VERSION ""

NS_ :

BS_:

BU_:
VAL_TABLE_ ETSD5_PRESSURE_Values 65024 "Sensor Elektric Alarm" 64768 "Sensor Not Calibrated" ;
VAL_TABLE_ ETSD3_DiagSteerRequest 4 "Diag Don't Move" 3 "Diag Centre" 2 "Diag Steer Right" 1 "Diag Steer Left" 0 "Diag Inactive" ;
VAL_TABLE_ SPEED_MidPointHyst 1 "Additional MidPointHyst On" 0 "Additional MidPointHyst Off" ;
VAL_TABLE_ SPEED_ValidIndication 4 "Two Reliable Speeds" 3 "One Reliable Speed" 2 "No Reliable Speed But Front Angl" 1 "No Reliable Speed" ;
VAL_TABLE_ SPEED_LeadSpeed 3 "No Valid Speed Decrement" 2 "Lead Speed " 1 "Lead Speed 1" 0 "No Speed Selected" ;
VAL_TABLE_ SPEED_InSpeed 255 "Knorr Kline no data for 80 ms" 254 "Knorr Kline no data in frame" 253 "Knorr Kline Framing Error" 252 "Knorr Kline Cs Error" 251 "Knorr Kline no header for 80ms" 250 "Speed Above 150 km/h" 249 "GPS No message(s) received" 248 "GPS No Fix" 247 "Can Signal not present" 246 "Can Signal not plausible" 245 "Wabco Pulse not present" 244 "Wabco Pulsetime below 150 ms" 243 "C3 Speed Deceleration rate too h" 242 "C3 Speed Kfactor out of range" 241 "C3 Speed Kfactor not stable" 240 "C3 Speed Kfactor not saved in ee" 239 "C3 Speed too loew for validation" ;
VAL_TABLE_ ETSD2_PRESSURE_Values 65024 "Sensor Elektric Alarm" 64768 "Sensor Not Calibrated" ;
VAL_TABLE_ ETSS_SimpleStatusses 32 "Normal" 12 "Normal" 11 "Failure" 10 "Crab" 9 "Manual" 8 "Centring" 7 "Unknown" 6 "Diagnostic" 5 "Failure" 4 "Waiting for Movement" 3 "Initialise" 2 "Checking..." 1 "Failure" 0 "Ok" ;
VAL_TABLE_ ETSD2_ANGLE_Values 65535 "Signal not available" 64510 "Not Defined" 64509 "Not Defined" 64508 "Not Defined" 64507 "Not Defined" 64506 "Not Defined" 64505 "Not Defined" 64504 "Not Defined" 64503 "Not Defined" 64502 "Not Defined" 64501 "Not Defined" 64500 "Not Defined" 64499 "Not Defined" 64498 "Not Defined" 64497 "Not Defined" 64496 "Not Defined" 64495 "Not Defined" 64494 "Not Defined" 64493 "Not Defined" 64492 "Not Defined" 64491 "Not Defined" 64490 "Not Defined" 64489 "Not Defined" 64488 "Not Defined" 64487 "Not Defined" 64486 "Not Defined" 64485 "Not Defined" 64484 "Not Defined" 64483 "Not Defined" 64482 "Not Defined" 64481 "Not Defined" 64480 "Not Defined" 64479 "Not Defined" 64478 "Not Defined" 64477 "Not Defined" 64476 "Not Defined" 64475 "Not Defined" 64474 "Not Defined" 64473 "Not Defined" 64472 "Not Defined" 64471 "Not Defined" 64470 "Not Defined" 64469 "Not Defined" 64468 "Not Defined" 64467 "Not Defined" 64466 "Not Defined" 64465 "Not Defined" 64464 "Not Defined" 64463 "Not Defined" 64462 "Not Defined" 64461 "Not Defined" 64460 "Not Defined" 64459 "Not Defined" 64458 "Not Defined" 64457 "Not Defined" 64456 "Not Defined" 64455 "Not Defined" 64454 "Not Defined" 64453 "Not Defined" 64452 "Not Defined" 64451 "Not Defined" 64450 "Not Defined" 64449 "Not Defined" 64448 "Not Defined" 64447 "Not Defined" 64446 "Not Defined" 64445 "Not Defined" 64444 "Not Defined" 64443 "Not Defined" 64442 "Not Defined" 64441 "Not Defined" 64440 "Not Defined" 64439 "Not Defined" 64438 "Not Defined" 64437 "Not Defined" 64436 "Not Defined" 64435 "Not Defined" 64434 "Not Defined" 64433 "Not Defined" 64432 "Not Defined" 64431 "Not Defined" 64430 "Not Defined" 64429 "Not Defined" 64428 "Not Defined" 64427 "Not Defined" 64426 "Not Defined" 64425 "Not Defined" 64424 "Not Defined" 64423 "Not Defined" 64422 "Not Defined" 64421 "Not Defined" 64420 "Not Defined" 64419 "Not Defined" 64418 "Not Defined" 64417 "Not Defined" 64416 "Not Defined" 64415 "Not Defined" 64414 "Not Defined" 64413 "Not Defined" 64412 "Not Defined" 64411 "Not Defined" 64410 "Not Defined" 64409 "Not Defined" 64408 "Not Defined" 64407 "Not Defined" 64406 "Not Defined" 64405 "Not Defined" 64404 "Not Defined" 64403 "Not Defined" 64402 "Not Defined" 64401 "Not Defined" 64400 "Not Defined" 64399 "Not Defined" 64398 "Not Defined" 64397 "Not Defined" 64396 "Not Defined" 64395 "Not Defined" 64394 "Not Defined" 64393 "Not Defined" 64392 "Not Defined" 64391 "Not Defined" 64390 "Not Defined" 64389 "Not Defined" 64388 "Not Defined" 64387 "Not Defined" 64386 "Not Defined" 64385 "Not Defined" 64384 "Not Defined" 64383 "Not Defined" 64382 "Not Defined" 64381 "Not Defined" 64380 "Not Defined" 64379 "Not Defined" 64378 "Not Defined" 64377 "Not Defined" 64376 "Not Defined" 64375 "Not Defined" 64374 "Not Defined" 64373 "Not Defined" 64372 "Not Defined" 64371 "Not Defined" 64370 "Not Defined" 64369 "Not Defined" 64368 "Not Defined" 64367 "Not Defined" 64366 "Not Defined" 64365 "Not Defined" 64364 "Not Defined" 64363 "Not Defined" 64362 "Not Defined" 64361 "Not Defined" 64360 "Not Defined" 64359 "Not Defined" 64358 "Not Defined" 64357 "Not Defined" 64356 "Not Defined" 64355 "Not Defined" 64354 "Not Defined" 64353 "Not Defined" 64352 "Not Defined" 64351 "Not Defined" 64350 "Not Defined" 64349 "Not Defined" 64348 "Not Defined" 64347 "Not Defined" 64346 "Not Defined" 64345 "Not Defined" 64344 "Not Defined" 64343 "Not Defined" 64342 "Not Defined" 64341 "Not Defined" 64340 "Not Defined" 64339 "Not Defined" 64338 "Not Defined" 64337 "Not Defined" 64336 "Not Defined" 64335 "Not Defined" 64334 "Not Defined" 64333 "Not Defined" 64332 "Not Defined" 64331 "Not Defined" 64330 "Not Defined" 64329 "Not Defined" 64328 "Not Defined" 64327 "Not Defined" 64326 "Not Defined" 64325 "Not Defined" 64324 "Not Defined" 64323 "Not Defined" 64322 "Not Defined" 64321 "Not Defined" 64320 "Not Defined" 64319 "Not Defined" 64318 "Not Defined" 64317 "Not Defined" 64316 "Not Defined" 64315 "Not Defined" 64314 "Not Defined" 64313 "Not Defined" 64312 "Not Defined" 64311 "Not Defined" 64310 "Not Defined" 64309 "Not Defined" 64308 "Not Defined" 64307 "Not Defined" 64306 "Not Defined" 64305 "Not Defined" 64304 "Not Defined" 64303 "Not Defined" 64302 "Not Defined" 64301 "Not Defined" 64300 "Not Defined" 64299 "Not Defined" 64298 "Not Defined" 64297 "Not Defined" 64296 "Not Defined" 64295 "Not Defined" 64294 "Not Defined" 64293 "Not Defined" 64292 "Not Defined" 64291 "Not Defined" 64290 "Not Defined" 64289 "Not Defined" 64288 "Not Defined" 64287 "Not Defined" 64286 "Not Defined" 64285 "Not Defined" 64284 "Not Defined" 64283 "Not Defined" 64282 "Not Defined" 64281 "Not Defined" 64280 "Not Defined" 64279 "Not Defined" 64278 "Not Defined" 64277 "Not Defined" 64276 "Not Defined" 64275 "Not Defined" 64274 "Not Defined" 64273 "Not Defined" 64272 "Not Defined" 64271 "Not Defined" 64270 "Not Defined" 64269 "Not Defined" 64268 "Not Defined" 64267 "Not Defined" 64266 "Not Defined" 64265 "Not Defined" 64264 "Not Defined" 64263 "Not Defined" 64262 "Not Defined" 64261 "Not Defined" 64260 "Not Defined" 64259 "Not Defined" 64258 "Not Defined" 64257 "Not Defined" 64256 "Not Defined" ;
VAL_TABLE_ ETSS_SteerMode_Values 15 "Not Defined" 14 "Not Defined" 13 "Not Defined" 12 "Not Defined" 11 "Not Defined" 10 "Not Defined" 9 "Not Defined" 8 "Not Defined" 7 "Not Defined" 6 "Not Defined" 5 "Not Defined" 4 "Not Defined" 3 "Not Defined" 2 "Crab " 1 "Normal" 0 "Manual" ;
VAL_TABLE_ ETSS_CentringState_Values 1 "ETS System is Active or Passive " 0 "Centring Steering Axle bij Centr" ;
VAL_TABLE_ ETSS_DiagnosticState_Values 1 "Diagnostic Session Active" 0 "No Diagnostic Session Active" ;
VAL_TABLE_ ETSS_AlarmState_Values 1 "Alarm(s) Active" 0 "No alarm active" ;
VAL_TABLE_ ETSS_SteeringState_Values 1 "ETS Operational" 0 "ETS Initialise" ;
VAL_TABLE_ ETSD1_ANGLE_Values 65535 "Signal not available" 64510 "Not Defined" 64509 "Not Defined" 64508 "Not Defined" 64507 "Not Defined" 64506 "Not Defined" 64505 "Not Defined" 64504 "Not Defined" 64503 "Not Defined" 64502 "Not Defined" 64501 "Not Defined" 64500 "Not Defined" 64499 "Not Defined" 64498 "Not Defined" 64497 "Not Defined" 64496 "Not Defined" 64495 "Not Defined" 64494 "Not Defined" 64493 "Not Defined" 64492 "Not Defined" 64491 "Not Defined" 64490 "Not Defined" 64489 "Not Defined" 64488 "Not Defined" 64487 "Not Defined" 64486 "Not Defined" 64485 "Not Defined" 64484 "Not Defined" 64483 "Not Defined" 64482 "Not Defined" 64481 "Not Defined" 64480 "Not Defined" 64479 "Not Defined" 64478 "Not Defined" 64477 "Not Defined" 64476 "Not Defined" 64475 "Not Defined" 64474 "Not Defined" 64473 "Not Defined" 64472 "Not Defined" 64471 "Not Defined" 64470 "Not Defined" 64469 "Not Defined" 64468 "Not Defined" 64467 "Not Defined" 64466 "Not Defined" 64465 "Not Defined" 64464 "Not Defined" 64463 "Not Defined" 64462 "Not Defined" 64461 "Not Defined" 64460 "Not Defined" 64459 "Not Defined" 64458 "Not Defined" 64457 "Not Defined" 64456 "Not Defined" 64455 "Not Defined" 64454 "Not Defined" 64453 "Not Defined" 64452 "Not Defined" 64451 "Not Defined" 64450 "Not Defined" 64449 "Not Defined" 64448 "Not Defined" 64447 "Not Defined" 64446 "Not Defined" 64445 "Not Defined" 64444 "Not Defined" 64443 "Not Defined" 64442 "Not Defined" 64441 "Not Defined" 64440 "Not Defined" 64439 "Not Defined" 64438 "Not Defined" 64437 "Not Defined" 64436 "Not Defined" 64435 "Not Defined" 64434 "Not Defined" 64433 "Not Defined" 64432 "Not Defined" 64431 "Not Defined" 64430 "Not Defined" 64429 "Not Defined" 64428 "Not Defined" 64427 "Not Defined" 64426 "Not Defined" 64425 "Not Defined" 64424 "Not Defined" 64423 "Not Defined" 64422 "Not Defined" 64421 "Not Defined" 64420 "Not Defined" 64419 "Not Defined" 64418 "Not Defined" 64417 "Not Defined" 64416 "Not Defined" 64415 "Not Defined" 64414 "Not Defined" 64413 "Not Defined" 64412 "Not Defined" 64411 "Not Defined" 64410 "Not Defined" 64409 "Not Defined" 64408 "Not Defined" 64407 "Not Defined" 64406 "Not Defined" 64405 "Not Defined" 64404 "Not Defined" 64403 "Not Defined" 64402 "Not Defined" 64401 "Not Defined" 64400 "Not Defined" 64399 "Not Defined" 64398 "Not Defined" 64397 "Not Defined" 64396 "Not Defined" 64395 "Not Defined" 64394 "Not Defined" 64393 "Not Defined" 64392 "Not Defined" 64391 "Not Defined" 64390 "Not Defined" 64389 "Not Defined" 64388 "Not Defined" 64387 "Not Defined" 64386 "Not Defined" 64385 "Not Defined" 64384 "Not Defined" 64383 "Not Defined" 64382 "Not Defined" 64381 "Not Defined" 64380 "Not Defined" 64379 "Not Defined" 64378 "Not Defined" 64377 "Not Defined" 64376 "Not Defined" 64375 "Not Defined" 64374 "Not Defined" 64373 "Not Defined" 64372 "Not Defined" 64371 "Not Defined" 64370 "Not Defined" 64369 "Not Defined" 64368 "Not Defined" 64367 "Not Defined" 64366 "Not Defined" 64365 "Not Defined" 64364 "Not Defined" 64363 "Not Defined" 64362 "Not Defined" 64361 "Not Defined" 64360 "Not Defined" 64359 "Not Defined" 64358 "Not Defined" 64357 "Not Defined" 64356 "Not Defined" 64355 "Not Defined" 64354 "Not Defined" 64353 "Not Defined" 64352 "Not Defined" 64351 "Not Defined" 64350 "Not Defined" 64349 "Not Defined" 64348 "Not Defined" 64347 "Not Defined" 64346 "Not Defined" 64345 "Not Defined" 64344 "Not Defined" 64343 "Not Defined" 64342 "Not Defined" 64341 "Not Defined" 64340 "Not Defined" 64339 "Not Defined" 64338 "Not Defined" 64337 "Not Defined" 64336 "Not Defined" 64335 "Not Defined" 64334 "Not Defined" 64333 "Not Defined" 64332 "Not Defined" 64331 "Not Defined" 64330 "Not Defined" 64329 "Not Defined" 64328 "Not Defined" 64327 "Not Defined" 64326 "Not Defined" 64325 "Not Defined" 64324 "Not Defined" 64323 "Not Defined" 64322 "Not Defined" 64321 "Not Defined" 64320 "Not Defined" 64319 "Not Defined" 64318 "Not Defined" 64317 "Not Defined" 64316 "Not Defined" 64315 "Not Defined" 64314 "Not Defined" 64313 "Not Defined" 64312 "Not Defined" 64311 "Not Defined" 64310 "Not Defined" 64309 "Not Defined" 64308 "Not Defined" 64307 "Not Defined" 64306 "Not Defined" 64305 "Not Defined" 64304 "Not Defined" 64303 "Not Defined" 64302 "Not Defined" 64301 "Not Defined" 64300 "Not Defined" 64299 "Not Defined" 64298 "Not Defined" 64297 "Not Defined" 64296 "Not Defined" 64295 "Not Defined" 64294 "Not Defined" 64293 "Not Defined" 64292 "Not Defined" 64291 "Not Defined" 64290 "Not Defined" 64289 "Not Defined" 64288 "Not Defined" 64287 "Not Defined" 64286 "Not Defined" 64285 "Not Defined" 64284 "Not Defined" 64283 "Not Defined" 64282 "Not Defined" 64281 "Not Defined" 64280 "Not Defined" 64279 "Not Defined" 64278 "Not Defined" 64277 "Not Defined" 64276 "Not Defined" 64275 "Not Defined" 64274 "Not Defined" 64273 "Not Defined" 64272 "Not Defined" 64271 "Not Defined" 64270 "Not Defined" 64269 "Not Defined" 64268 "Not Defined" 64267 "Not Defined" 64266 "Not Defined" 64265 "Not Defined" 64264 "Not Defined" 64263 "Not Defined" 64262 "Not Defined" 64261 "Not Defined" 64260 "Not Defined" 64259 "Not Defined" 64258 "Not Defined" 64257 "Not Defined" 64256 "Not Defined" ;
VAL_TABLE_ ETSD1_SPEED_Values 255 "Signal not Available" 254 "not defined" 253 "not defined" 252 "not defined" 251 "not defined" ;
VAL_TABLE_ KSD_Values 255 "Signal not Available" 254 "not defined" 253 "not defined" 252 "not defined" 251 "not defined" ;
VAL_TABLE_ DIV_Values 3 "Signal not Available" 2 "Failure/Incorrect Status" 1 "Input is High" 0 "Input is Low" ;
VAL_TABLE_ AIV_Values 65534 "Not Defined" 65533 "Not Defined" 65532 "Not Defined" 65531 "Not Defined" 65530 "Not Defined" 65529 "Not Defined" 65528 "Not Defined" 65527 "Not Defined" 65526 "Not Defined" 65525 "Not Defined" 65524 "Not Defined" 65523 "Not Defined" 65522 "Not Defined" 65521 "Not Defined" 65520 "Not Defined" 65519 "Not Defined" 65518 "Not Defined" 65517 "Not Defined" 65516 "Not Defined" 65515 "Not Defined" 65514 "Not Defined" 65513 "Not Defined" 65512 "Not Defined" 65511 "Not Defined" 65510 "Not Defined" 65509 "Not Defined" 65508 "Not Defined" 65507 "Not Defined" 65506 "Not Defined" 65505 "Not Defined" 65504 "Not Defined" 65503 "Not Defined" 65502 "Not Defined" 65501 "Not Defined" 65500 "Not Defined" 65499 "Not Defined" 65498 "Not Defined" 65497 "Not Defined" 65496 "Not Defined" 65495 "Not Defined" 65494 "Not Defined" 65493 "Not Defined" 65492 "Not Defined" 65491 "Not Defined" 65490 "Not Defined" 65489 "Not Defined" 65488 "Not Defined" 65487 "Not Defined" 65486 "Not Defined" 65485 "Not Defined" 65484 "Not Defined" 65483 "Not Defined" 65482 "Not Defined" 65481 "Not Defined" 65480 "Not Defined" 65479 "Not Defined" 65478 "Not Defined" 65477 "Not Defined" 65476 "Not Defined" 65475 "Not Defined" 65474 "Not Defined" 65473 "Not Defined" 65472 "Not Defined" 65471 "Not Defined" 65470 "Not Defined" 65469 "Not Defined" 65468 "Not Defined" 65467 "Not Defined" 65466 "Not Defined" 65465 "Not Defined" 65464 "Not Defined" 65463 "Not Defined" 65462 "Not Defined" 65461 "Not Defined" 65460 "Not Defined" 65459 "Not Defined" 65458 "Not Defined" 65457 "Not Defined" 65456 "Not Defined" 65455 "Not Defined" 65454 "Not Defined" 65453 "Not Defined" 65452 "Not Defined" 65451 "Not Defined" 65450 "Not Defined" 65449 "Not Defined" 65448 "Not Defined" 65447 "Not Defined" 65446 "Not Defined" 65445 "Not Defined" 65444 "Not Defined" 65443 "Not Defined" 65442 "Not Defined" 65441 "Not Defined" 65440 "Not Defined" 65439 "Not Defined" 65438 "Not Defined" 65437 "Not Defined" 65436 "Not Defined" 65435 "Not Defined" 65434 "Not Defined" 65433 "Not Defined" 65432 "Not Defined" 65431 "Not Defined" 65430 "Not Defined" 65429 "Not Defined" 65428 "Not Defined" 65427 "Not Defined" 65426 "Not Defined" 65425 "Not Defined" 65424 "Not Defined" 65423 "Not Defined" 65422 "Not Defined" 65421 "Not Defined" 65420 "Not Defined" 65419 "Not Defined" 65418 "Not Defined" 65417 "Not Defined" 65416 "Not Defined" 65415 "Not Defined" 65414 "Not Defined" 65413 "Not Defined" 65412 "Not Defined" 65411 "Not Defined" 65410 "Not Defined" 65409 "Not Defined" 65408 "Not Defined" 65407 "Not Defined" 65406 "Not Defined" 65405 "Not Defined" 65404 "Not Defined" 65403 "Not Defined" 65402 "Not Defined" 65401 "Not Defined" 65400 "Not Defined" 65399 "Not Defined" 65398 "Not Defined" 65397 "Not Defined" 65396 "Not Defined" 65395 "Not Defined" 65394 "Not Defined" 65393 "Not Defined" 65392 "Not Defined" 65391 "Not Defined" 65390 "Not Defined" 65389 "Not Defined" 65388 "Not Defined" 65387 "Not Defined" 65386 "Not Defined" 65385 "Not Defined" 65384 "Not Defined" 65383 "Not Defined" 65382 "Not Defined" 65381 "Not Defined" 65380 "Not Defined" 65379 "Not Defined" 65378 "Not Defined" 65377 "Not Defined" 65376 "Not Defined" 65375 "Not Defined" 65374 "Not Defined" 65373 "Not Defined" 65372 "Not Defined" 65371 "Not Defined" 65370 "Not Defined" 65369 "Not Defined" 65368 "Not Defined" 65367 "Not Defined" 65366 "Not Defined" 65365 "Not Defined" 65364 "Not Defined" 65363 "Not Defined" 65362 "Not Defined" 65361 "Not Defined" 65360 "Not Defined" 65359 "Not Defined" 65358 "Not Defined" 65357 "Not Defined" 65356 "Not Defined" 65355 "Not Defined" 65354 "Not Defined" 65353 "Not Defined" 65352 "Not Defined" 65351 "Not Defined" 65350 "Not Defined" 65349 "Not Defined" 65348 "Not Defined" 65347 "Not Defined" 65346 "Not Defined" 65345 "Not Defined" 65344 "Not Defined" 65343 "Not Defined" 65342 "Not Defined" 65341 "Not Defined" 65340 "Not Defined" 65339 "Not Defined" 65338 "Not Defined" 65337 "Not Defined" 65336 "Not Defined" 65335 "Not Defined" 65334 "Not Defined" 65333 "Not Defined" 65332 "Not Defined" 65331 "Not Defined" 65330 "Not Defined" 65329 "Not Defined" 65328 "Not Defined" 65327 "Not Defined" 65326 "Not Defined" 65325 "Not Defined" 65324 "Not Defined" 65323 "Not Defined" 65322 "Not Defined" 65321 "Not Defined" 65320 "Not Defined" 65319 "Not Defined" 65318 "Not Defined" 65317 "Not Defined" 65316 "Not Defined" 65315 "Not Defined" 65314 "Not Defined" 65313 "Not Defined" 65312 "Not Defined" 65311 "Not Defined" 65310 "Not Defined" 65309 "Not Defined" 65308 "Not Defined" 65307 "Not Defined" 65306 "Not Defined" 65305 "Not Defined" 65304 "Not Defined" 65303 "Not Defined" 65302 "Not Defined" 65301 "Not Defined" 65300 "Not Defined" 65299 "Not Defined" 65298 "Not Defined" 65297 "Not Defined" 65296 "Not Defined" 65295 "Not Defined" 65294 "Not Defined" 65293 "Not Defined" 65292 "Not Defined" 65291 "Not Defined" 65290 "Not Defined" 65289 "Not Defined" 65288 "Not Defined" 65287 "Not Defined" 65286 "Not Defined" 65285 "Not Defined" 65284 "Not Defined" 65283 "Not Defined" 65282 "Not Defined" 65281 "Not Defined" 65280 "Not Defined" 65279 "Not Defined" 65278 "Not Defined" 65277 "Not Defined" 65276 "Not Defined" 65275 "Not Defined" 65274 "Not Defined" 65273 "Not Defined" 65272 "Not Defined" 65271 "Not Defined" 65270 "Not Defined" 65269 "Not Defined" 65268 "Not Defined" 65267 "Not Defined" 65266 "Not Defined" 65265 "Not Defined" 65264 "Not Defined" 65263 "Not Defined" 65262 "Not Defined" 65261 "Not Defined" 65260 "Not Defined" 65259 "Not Defined" 65258 "Not Defined" 65257 "Not Defined" 65256 "Not Defined" 65255 "Not Defined" 65254 "Not Defined" 65253 "Not Defined" 65252 "Not Defined" 65251 "Not Defined" 65250 "Not Defined" 65249 "Not Defined" 65248 "Not Defined" 65247 "Not Defined" 65246 "Not Defined" 65245 "Not Defined" 65244 "Not Defined" 65243 "Not Defined" 65242 "Not Defined" 65241 "Not Defined" 65240 "Not Defined" 65239 "Not Defined" 65238 "Not Defined" 65237 "Not Defined" 65236 "Not Defined" 65235 "Not Defined" 65234 "Not Defined" 65233 "Not Defined" 65232 "Not Defined" 65231 "Not Defined" 65230 "Not Defined" 65229 "Not Defined" 65228 "Not Defined" 65227 "Not Defined" 65226 "Not Defined" 65225 "Not Defined" 65224 "Not Defined" 65223 "Not Defined" 65222 "Not Defined" 65221 "Not Defined" 65220 "Not Defined" 65219 "Not Defined" 65218 "Not Defined" 65217 "Not Defined" 65216 "Not Defined" 65215 "Not Defined" 65214 "Not Defined" 65213 "Not Defined" 65212 "Not Defined" 65211 "Not Defined" 65210 "Not Defined" 65209 "Not Defined" 65208 "Not Defined" 65207 "Not Defined" 65206 "Not Defined" 65205 "Not Defined" 65204 "Not Defined" 65203 "Not Defined" 65202 "Not Defined" 65201 "Not Defined" 65200 "Not Defined" 65199 "Not Defined" 65198 "Not Defined" 65197 "Not Defined" 65196 "Not Defined" 65195 "Not Defined" 65194 "Not Defined" 65193 "Not Defined" 65192 "Not Defined" 65191 "Not Defined" 65190 "Not Defined" 65189 "Not Defined" 65188 "Not Defined" 65187 "Not Defined" 65186 "Not Defined" 65185 "Not Defined" 65184 "Not Defined" 65183 "Not Defined" 65182 "Not Defined" 65181 "Not Defined" 65180 "Not Defined" 65179 "Not Defined" 65178 "Not Defined" 65177 "Not Defined" 65176 "Not Defined" 65175 "Not Defined" 65174 "Not Defined" 65173 "Not Defined" 65172 "Not Defined" 65171 "Not Defined" 65170 "Not Defined" 65169 "Not Defined" 65168 "Not Defined" 65167 "Not Defined" 65166 "Not Defined" 65165 "Not Defined" 65164 "Not Defined" 65163 "Not Defined" 65162 "Not Defined" 65161 "Not Defined" 65160 "Not Defined" 65159 "Not Defined" 65158 "Not Defined" 65157 "Not Defined" 65156 "Not Defined" 65155 "Not Defined" 65154 "Not Defined" 65153 "Not Defined" 65152 "Not Defined" 65151 "Not Defined" 65150 "Not Defined" 65149 "Not Defined" 65148 "Not Defined" 65147 "Not Defined" 65146 "Not Defined" 65145 "Not Defined" 65144 "Not Defined" 65143 "Not Defined" 65142 "Not Defined" 65141 "Not Defined" 65140 "Not Defined" 65139 "Not Defined" 65138 "Not Defined" 65137 "Not Defined" 65136 "Not Defined" 65135 "Not Defined" 65134 "Not Defined" 65133 "Not Defined" 65132 "Not Defined" 65131 "Not Defined" 65130 "Not Defined" 65129 "Not Defined" 65128 "Not Defined" 65127 "Not Defined" 65126 "Not Defined" 65125 "Not Defined" 65124 "Not Defined" 65123 "Not Defined" 65122 "Not Defined" 65121 "Not Defined" 65120 "Not Defined" 65119 "Not Defined" 65118 "Not Defined" 65117 "Not Defined" 65116 "Not Defined" 65115 "Not Defined" 65114 "Not Defined" 65113 "Not Defined" 65112 "Not Defined" 65111 "Not Defined" 65110 "Not Defined" 65109 "Not Defined" 65108 "Not Defined" 65107 "Not Defined" 65106 "Not Defined" 65105 "Not Defined" 65104 "Not Defined" 65103 "Not Defined" 65102 "Not Defined" 65101 "Not Defined" 65100 "Not Defined" 65099 "Not Defined" 65098 "Not Defined" 65097 "Not Defined" 65096 "Not Defined" 65095 "Not Defined" 65094 "Not Defined" 65093 "Not Defined" 65092 "Not Defined" 65091 "Not Defined" 65090 "Not Defined" 65089 "Not Defined" 65088 "Not Defined" 65087 "Not Defined" 65086 "Not Defined" 65085 "Not Defined" 65084 "Not Defined" 65083 "Not Defined" 65082 "Not Defined" 65081 "Not Defined" 65080 "Not Defined" 65079 "Not Defined" 65078 "Not Defined" 65077 "Not Defined" 65076 "Not Defined" 65075 "Not Defined" 65074 "Not Defined" 65073 "Not Defined" 65072 "Not Defined" 65071 "Not Defined" 65070 "Not Defined" 65069 "Not Defined" 65068 "Not Defined" 65067 "Not Defined" 65066 "Not Defined" 65065 "Not Defined" 65064 "Not Defined" 65063 "Not Defined" 65062 "Not Defined" 65061 "Not Defined" 65060 "Not Defined" 65059 "Not Defined" 65058 "Not Defined" 65057 "Not Defined" 65056 "Not Defined" 65055 "Not Defined" 65054 "Not Defined" 65053 "Not Defined" 65052 "Not Defined" 65051 "Not Defined" 65050 "Not Defined" 65049 "Not Defined" 65048 "Not Defined" 65047 "Not Defined" 65046 "Not Defined" 65045 "Not Defined" 65044 "Not Defined" 65043 "Not Defined" 65042 "Not Defined" 65041 "Not Defined" 65040 "Not Defined" 65039 "Not Defined" 65038 "Not Defined" 65037 "Not Defined" 65036 "Not Defined" 65035 "Not Defined" 65034 "Not Defined" 65033 "Not Defined" 65032 "Not Defined" 65031 "Not Defined" 65030 "Not Defined" 65029 "Not Defined" 65028 "Not Defined" 65027 "Not Defined" 65026 "Not Defined" 65025 "Not Defined" 65024 "Not Defined" 65023 "Not Defined" 65022 "Not Defined" 65021 "Not Defined" 65020 "Not Defined" 65019 "Not Defined" 65018 "Not Defined" 65017 "Not Defined" 65016 "Not Defined" 65015 "Not Defined" 65014 "Not Defined" 65013 "Not Defined" 65012 "Not Defined" 65011 "Not Defined" 65010 "Not Defined" 65009 "Not Defined" 65008 "Not Defined" 65007 "Not Defined" 65006 "Not Defined" 65005 "Not Defined" 65004 "Not Defined" 65003 "Not Defined" 65002 "Not Defined" 65001 "Not Defined" 65000 "Not Defined" 64999 "Not Defined" 64998 "Not Defined" 64997 "Not Defined" 64996 "Not Defined" 64995 "Not Defined" 64994 "Not Defined" 64993 "Not Defined" 64992 "Not Defined" 64991 "Not Defined" 64990 "Not Defined" 64989 "Not Defined" 64988 "Not Defined" 64987 "Not Defined" 64986 "Not Defined" 64985 "Not Defined" 64984 "Not Defined" 64983 "Not Defined" 64982 "Not Defined" 64981 "Not Defined" 64980 "Not Defined" 64979 "Not Defined" 64978 "Not Defined" 64977 "Not Defined" 64976 "Not Defined" 64975 "Not Defined" 64974 "Not Defined" 64973 "Not Defined" 64972 "Not Defined" 64971 "Not Defined" 64970 "Not Defined" 64969 "Not Defined" 64968 "Not Defined" 64967 "Not Defined" 64966 "Not Defined" 64965 "Not Defined" 64964 "Not Defined" 64963 "Not Defined" 64962 "Not Defined" 64961 "Not Defined" 64960 "Not Defined" 64959 "Not Defined" 64958 "Not Defined" 64957 "Not Defined" 64956 "Not Defined" 64955 "Not Defined" 64954 "Not Defined" 64953 "Not Defined" 64952 "Not Defined" 64951 "Not Defined" 64950 "Not Defined" 64949 "Not Defined" 64948 "Not Defined" 64947 "Not Defined" 64946 "Not Defined" 64945 "Not Defined" 64944 "Not Defined" 64943 "Not Defined" 64942 "Not Defined" 64941 "Not Defined" 64940 "Not Defined" 64939 "Not Defined" 64938 "Not Defined" 64937 "Not Defined" 64936 "Not Defined" 64935 "Not Defined" 64934 "Not Defined" 64933 "Not Defined" 64932 "Not Defined" 64931 "Not Defined" 64930 "Not Defined" 64929 "Not Defined" 64928 "Not Defined" 64927 "Not Defined" 64926 "Not Defined" 64925 "Not Defined" 64924 "Not Defined" 64923 "Not Defined" 64922 "Not Defined" 64921 "Not Defined" 64920 "Not Defined" 64919 "Not Defined" 64918 "Not Defined" 64917 "Not Defined" 64916 "Not Defined" 64915 "Not Defined" 64914 "Not Defined" 64913 "Not Defined" 64912 "Not Defined" 64911 "Not Defined" 64910 "Not Defined" 64909 "Not Defined" 64908 "Not Defined" 64907 "Not Defined" 64906 "Not Defined" 64905 "Not Defined" 64904 "Not Defined" 64903 "Not Defined" 64902 "Not Defined" 64901 "Not Defined" 64900 "Not Defined" 64899 "Not Defined" 64898 "Not Defined" 64897 "Not Defined" 64896 "Not Defined" 64895 "Not Defined" 64894 "Not Defined" 64893 "Not Defined" 64892 "Not Defined" 64891 "Not Defined" 64890 "Not Defined" 64889 "Not Defined" 64888 "Not Defined" 64887 "Not Defined" 64886 "Not Defined" 64885 "Not Defined" 64884 "Not Defined" 64883 "Not Defined" 64882 "Not Defined" 64881 "Not Defined" 64880 "Not Defined" 64879 "Not Defined" 64878 "Not Defined" 64877 "Not Defined" 64876 "Not Defined" 64875 "Not Defined" 64874 "Not Defined" 64873 "Not Defined" 64872 "Not Defined" 64871 "Not Defined" 64870 "Not Defined" 64869 "Not Defined" 64868 "Not Defined" 64867 "Not Defined" 64866 "Not Defined" 64865 "Not Defined" 64864 "Not Defined" 64863 "Not Defined" 64862 "Not Defined" 64861 "Not Defined" 64860 "Not Defined" 64859 "Not Defined" 64858 "Not Defined" 64857 "Not Defined" 64856 "Not Defined" 64855 "Not Defined" 64854 "Not Defined" 64853 "Not Defined" 64852 "Not Defined" 64851 "Not Defined" 64850 "Not Defined" 64849 "Not Defined" 64848 "Not Defined" 64847 "Not Defined" 64846 "Not Defined" 64845 "Not Defined" 64844 "Not Defined" 64843 "Not Defined" 64842 "Not Defined" 64841 "Not Defined" 64840 "Not Defined" 64839 "Not Defined" 64838 "Not Defined" 64837 "Not Defined" 64836 "Not Defined" 64835 "Not Defined" 64834 "Not Defined" 64833 "Not Defined" 64832 "Not Defined" 64831 "Not Defined" 64830 "Not Defined" 64829 "Not Defined" 64828 "Not Defined" 64827 "Not Defined" 64826 "Not Defined" 64825 "Not Defined" 64824 "Not Defined" 64823 "Not Defined" 64822 "Not Defined" 64821 "Not Defined" 64820 "Not Defined" 64819 "Not Defined" 64818 "Not Defined" 64817 "Not Defined" 64816 "Not Defined" 64815 "Not Defined" 64814 "Not Defined" 64813 "Not Defined" 64812 "Not Defined" 64811 "Not Defined" 64810 "Not Defined" 64809 "Not Defined" 64808 "Not Defined" 64807 "Not Defined" 64806 "Not Defined" 64805 "Not Defined" 64804 "Not Defined" 64803 "Not Defined" 64802 "Not Defined" 64801 "Not Defined" 64800 "Not Defined" 64799 "Not Defined" 64798 "Not Defined" 64797 "Not Defined" 64796 "Not Defined" 64795 "Not Defined" 64794 "Not Defined" 64793 "Not Defined" 64792 "Not Defined" 64791 "Not Defined" 64790 "Not Defined" 64789 "Not Defined" 64788 "Not Defined" 64787 "Not Defined" 64786 "Not Defined" 64785 "Not Defined" 64784 "Not Defined" 64783 "Not Defined" 64782 "Not Defined" 64781 "Not Defined" 64780 "Not Defined" 64779 "Not Defined" 64778 "Not Defined" 64777 "Not Defined" 64776 "Not Defined" 64775 "Not Defined" 64774 "Not Defined" 64773 "Not Defined" 64772 "Not Defined" 64771 "Not Defined" 64770 "Not Defined" 64769 "Not Defined" 64768 "Not Defined" 64767 "Not Defined" 64766 "Not Defined" 64765 "Not Defined" 64764 "Not Defined" 64763 "Not Defined" 64762 "Not Defined" 64761 "Not Defined" 64760 "Not Defined" 64759 "Not Defined" 64758 "Not Defined" 64757 "Not Defined" 64756 "Not Defined" 64755 "Not Defined" 64754 "Not Defined" 64753 "Not Defined" 64752 "Not Defined" 64751 "Not Defined" 64750 "Not Defined" 64749 "Not Defined" 64748 "Not Defined" 64747 "Not Defined" 64746 "Not Defined" 64745 "Not Defined" 64744 "Not Defined" 64743 "Not Defined" 64742 "Not Defined" 64741 "Not Defined" 64740 "Not Defined" 64739 "Not Defined" 64738 "Not Defined" 64737 "Not Defined" 64736 "Not Defined" 64735 "Not Defined" 64734 "Not Defined" 64733 "Not Defined" 64732 "Not Defined" 64731 "Not Defined" 64730 "Not Defined" 64729 "Not Defined" 64728 "Not Defined" 64727 "Not Defined" 64726 "Not Defined" 64725 "Not Defined" 64724 "Not Defined" 64723 "Not Defined" 64722 "Not Defined" 64721 "Not Defined" 64720 "Not Defined" 64719 "Not Defined" 64718 "Not Defined" 64717 "Not Defined" 64716 "Not Defined" 64715 "Not Defined" 64714 "Not Defined" 64713 "Not Defined" 64712 "Not Defined" 64711 "Not Defined" 64710 "Not Defined" 64709 "Not Defined" 64708 "Not Defined" 64707 "Not Defined" 64706 "Not Defined" 64705 "Not Defined" 64704 "Not Defined" 64703 "Not Defined" 64702 "Not Defined" 64701 "Not Defined" 64700 "Not Defined" 64699 "Not Defined" 64698 "Not Defined" 64697 "Not Defined" 64696 "Not Defined" 64695 "Not Defined" 64694 "Not Defined" 64693 "Not Defined" 64692 "Not Defined" 64691 "Not Defined" 64690 "Not Defined" 64689 "Not Defined" 64688 "Not Defined" 64687 "Not Defined" 64686 "Not Defined" 64685 "Not Defined" 64684 "Not Defined" 64683 "Not Defined" 64682 "Not Defined" 64681 "Not Defined" 64680 "Not Defined" 64679 "Not Defined" 64678 "Not Defined" 64677 "Not Defined" 64676 "Not Defined" 64675 "Not Defined" 64674 "Not Defined" 64673 "Not Defined" 64672 "Not Defined" 64671 "Not Defined" 64670 "Not Defined" 64669 "Not Defined" 64668 "Not Defined" 64667 "Not Defined" 64666 "Not Defined" 64665 "Not Defined" 64664 "Not Defined" 64663 "Not Defined" 64662 "Not Defined" 64661 "Not Defined" 64660 "Not Defined" 64659 "Not Defined" 64658 "Not Defined" 64657 "Not Defined" 64656 "Not Defined" 64655 "Not Defined" 64654 "Not Defined" 64653 "Not Defined" 64652 "Not Defined" 64651 "Not Defined" 64650 "Not Defined" 64649 "Not Defined" 64648 "Not Defined" 64647 "Not Defined" 64646 "Not Defined" 64645 "Not Defined" 64644 "Not Defined" 64643 "Not Defined" 64642 "Not Defined" 64641 "Not Defined" 64640 "Not Defined" 64639 "Not Defined" 64638 "Not Defined" 64637 "Not Defined" 64636 "Not Defined" 64635 "Not Defined" 64634 "Not Defined" 64633 "Not Defined" 64632 "Not Defined" 64631 "Not Defined" 64630 "Not Defined" 64629 "Not Defined" 64628 "Not Defined" 64627 "Not Defined" 64626 "Not Defined" 64625 "Not Defined" 64624 "Not Defined" 64623 "Not Defined" 64622 "Not Defined" 64621 "Not Defined" 64620 "Not Defined" 64619 "Not Defined" 64618 "Not Defined" 64617 "Not Defined" 64616 "Not Defined" 64615 "Not Defined" 64614 "Not Defined" 64613 "Not Defined" 64612 "Not Defined" 64611 "Not Defined" 64610 "Not Defined" 64609 "Not Defined" 64608 "Not Defined" 64607 "Not Defined" 64606 "Not Defined" 64605 "Not Defined" 64604 "Not Defined" 64603 "Not Defined" 64602 "Not Defined" 64601 "Not Defined" 64600 "Not Defined" 64599 "Not Defined" 64598 "Not Defined" 64597 "Not Defined" 64596 "Not Defined" 64595 "Not Defined" 64594 "Not Defined" 64593 "Not Defined" 64592 "Not Defined" 64591 "Not Defined" 64590 "Not Defined" 64589 "Not Defined" 64588 "Not Defined" 64587 "Not Defined" 64586 "Not Defined" 64585 "Not Defined" 64584 "Not Defined" 64583 "Not Defined" 64582 "Not Defined" 64581 "Not Defined" 64580 "Not Defined" 64579 "Not Defined" 64578 "Not Defined" 64577 "Not Defined" 64576 "Not Defined" 64575 "Not Defined" 64574 "Not Defined" 64573 "Not Defined" 64572 "Not Defined" 64571 "Not Defined" 64570 "Not Defined" 64569 "Not Defined" 64568 "Not Defined" 64567 "Not Defined" 64566 "Not Defined" 64565 "Not Defined" 64564 "Not Defined" 64563 "Not Defined" 64562 "Not Defined" 64561 "Not Defined" 64560 "Not Defined" 64559 "Not Defined" 64558 "Not Defined" 64557 "Not Defined" 64556 "Not Defined" 64555 "Not Defined" 64554 "Not Defined" 64553 "Not Defined" 64552 "Not Defined" 64551 "Not Defined" 64550 "Not Defined" 64549 "Not Defined" 64548 "Not Defined" 64547 "Not Defined" 64546 "Not Defined" 64545 "Not Defined" 64544 "Not Defined" 64543 "Not Defined" 64542 "Not Defined" 64541 "Not Defined" 64540 "Not Defined" 64539 "Not Defined" 64538 "Not Defined" 64537 "Not Defined" 64536 "Not Defined" 64535 "Not Defined" 64534 "Not Defined" 64533 "Not Defined" 64532 "Not Defined" 64531 "Not Defined" 64530 "Not Defined" 64529 "Not Defined" 64528 "Not Defined" 64527 "Not Defined" 64526 "Not Defined" 64525 "Not Defined" 64524 "Not Defined" 64523 "Not Defined" 64522 "Not Defined" 64521 "Not Defined" 64520 "Not Defined" 64519 "Not Defined" 64518 "Not Defined" 64517 "Not Defined" 64516 "Not Defined" 64515 "Not Defined" 64514 "Not Defined" 64513 "Not Defined" 64512 "Not Defined" 64511 "Not Defined" 65535 "Signal not available" 64510 "Not Defined" 64509 "Not Defined" 64508 "Not Defined" 64507 "Not Defined" 64506 "Not Defined" 64505 "Not Defined" 64504 "Not Defined" 64503 "Not Defined" 64502 "Not Defined" 64501 "Not Defined" 64500 "Not Defined" 64499 "Not Defined" 64498 "Not Defined" 64497 "Not Defined" 64496 "Not Defined" 64495 "Not Defined" 64494 "Not Defined" 64493 "Not Defined" 64492 "Not Defined" 64491 "Not Defined" 64490 "Not Defined" 64489 "Not Defined" 64488 "Not Defined" 64487 "Not Defined" 64486 "Not Defined" 64485 "Not Defined" 64484 "Not Defined" 64483 "Not Defined" 64482 "Not Defined" 64481 "Not Defined" 64480 "Not Defined" 64479 "Not Defined" 64478 "Not Defined" 64477 "Not Defined" 64476 "Not Defined" 64475 "Not Defined" 64474 "Not Defined" 64473 "Not Defined" 64472 "Not Defined" 64471 "Not Defined" 64470 "Not Defined" 64469 "Not Defined" 64468 "Not Defined" 64467 "Not Defined" 64466 "Not Defined" 64465 "Not Defined" 64464 "Not Defined" 64463 "Not Defined" 64462 "Not Defined" 64461 "Not Defined" 64460 "Not Defined" 64459 "Not Defined" 64458 "Not Defined" 64457 "Not Defined" 64456 "Not Defined" 64455 "Not Defined" 64454 "Not Defined" 64453 "Not Defined" 64452 "Not Defined" 64451 "Not Defined" 64450 "Not Defined" 64449 "Not Defined" 64448 "Not Defined" 64447 "Not Defined" 64446 "Not Defined" 64445 "Not Defined" 64444 "Not Defined" 64443 "Not Defined" 64442 "Not Defined" 64441 "Not Defined" 64440 "Not Defined" 64439 "Not Defined" 64438 "Not Defined" 64437 "Not Defined" 64436 "Not Defined" 64435 "Not Defined" 64434 "Not Defined" 64433 "Not Defined" 64432 "Not Defined" 64431 "Not Defined" 64430 "Not Defined" 64429 "Not Defined" 64428 "Not Defined" 64427 "Not Defined" 64426 "Not Defined" 64425 "Not Defined" 64424 "Not Defined" 64423 "Not Defined" 64422 "Not Defined" 64421 "Not Defined" 64420 "Not Defined" 64419 "Not Defined" 64418 "Not Defined" 64417 "Not Defined" 64416 "Not Defined" 64415 "Not Defined" 64414 "Not Defined" 64413 "Not Defined" 64412 "Not Defined" 64411 "Not Defined" 64410 "Not Defined" 64409 "Not Defined" 64408 "Not Defined" 64407 "Not Defined" 64406 "Not Defined" 64405 "Not Defined" 64404 "Not Defined" 64403 "Not Defined" 64402 "Not Defined" 64401 "Not Defined" 64400 "Not Defined" 64399 "Not Defined" 64398 "Not Defined" 64397 "Not Defined" 64396 "Not Defined" 64395 "Not Defined" 64394 "Not Defined" 64393 "Not Defined" 64392 "Not Defined" 64391 "Not Defined" 64390 "Not Defined" 64389 "Not Defined" 64388 "Not Defined" 64387 "Not Defined" 64386 "Not Defined" 64385 "Not Defined" 64384 "Not Defined" 64383 "Not Defined" 64382 "Not Defined" 64381 "Not Defined" 64380 "Not Defined" 64379 "Not Defined" 64378 "Not Defined" 64377 "Not Defined" 64376 "Not Defined" 64375 "Not Defined" 64374 "Not Defined" 64373 "Not Defined" 64372 "Not Defined" 64371 "Not Defined" 64370 "Not Defined" 64369 "Not Defined" 64368 "Not Defined" 64367 "Not Defined" 64366 "Not Defined" 64365 "Not Defined" 64364 "Not Defined" 64363 "Not Defined" 64362 "Not Defined" 64361 "Not Defined" 64360 "Not Defined" 64359 "Not Defined" 64358 "Not Defined" 64357 "Not Defined" 64356 "Not Defined" 64355 "Not Defined" 64354 "Not Defined" 64353 "Not Defined" 64352 "Not Defined" 64351 "Not Defined" 64350 "Not Defined" 64349 "Not Defined" 64348 "Not Defined" 64347 "Not Defined" 64346 "Not Defined" 64345 "Not Defined" 64344 "Not Defined" 64343 "Not Defined" 64342 "Not Defined" 64341 "Not Defined" 64340 "Not Defined" 64339 "Not Defined" 64338 "Not Defined" 64337 "Not Defined" 64336 "Not Defined" 64335 "Not Defined" 64334 "Not Defined" 64333 "Not Defined" 64332 "Not Defined" 64331 "Not Defined" 64330 "Not Defined" 64329 "Not Defined" 64328 "Not Defined" 64327 "Not Defined" 64326 "Not Defined" 64325 "Not Defined" 64324 "Not Defined" 64323 "Not Defined" 64322 "Not Defined" 64321 "Not Defined" 64320 "Not Defined" 64319 "Not Defined" 64318 "Not Defined" 64317 "Not Defined" 64316 "Not Defined" 64315 "Not Defined" 64314 "Not Defined" 64313 "Not Defined" 64312 "Not Defined" 64311 "Not Defined" 64310 "Not Defined" 64309 "Not Defined" 64308 "Not Defined" 64307 "Not Defined" 64306 "Not Defined" 64305 "Not Defined" 64304 "Not Defined" 64303 "Not Defined" 64302 "Not Defined" 64301 "Not Defined" 64300 "Not Defined" 64299 "Not Defined" 64298 "Not Defined" 64297 "Not Defined" 64296 "Not Defined" 64295 "Not Defined" 64294 "Not Defined" 64293 "Not Defined" 64292 "Not Defined" 64291 "Not Defined" 64290 "Not Defined" 64289 "Not Defined" 64288 "Not Defined" 64287 "Not Defined" 64286 "Not Defined" 64285 "Not Defined" 64284 "Not Defined" 64283 "Not Defined" 64282 "Not Defined" 64281 "Not Defined" 64280 "Not Defined" 64279 "Not Defined" 64278 "Not Defined" 64277 "Not Defined" 64276 "Not Defined" 64275 "Not Defined" 64274 "Not Defined" 64273 "Not Defined" 64272 "Not Defined" 64271 "Not Defined" 64270 "Not Defined" 64269 "Not Defined" 64268 "Not Defined" 64267 "Not Defined" 64266 "Not Defined" 64265 "Not Defined" 64264 "Not Defined" 64263 "Not Defined" 64262 "Not Defined" 64261 "Not Defined" 64260 "Not Defined" 64259 "Not Defined" 64258 "Not Defined" 64257 "Not Defined" 64256 "Not Defined" ;
VAL_TABLE_ PSV_Values 65535 "Signal not available" 64510 "Not Defined" 64509 "Not Defined" 64508 "Not Defined" 64507 "Not Defined" 64506 "Not Defined" 64505 "Not Defined" 64504 "Not Defined" 64503 "Not Defined" 64502 "Not Defined" 64501 "Not Defined" 64500 "Not Defined" 64499 "Not Defined" 64498 "Not Defined" 64497 "Not Defined" 64496 "Not Defined" 64495 "Not Defined" 64494 "Not Defined" 64493 "Not Defined" 64492 "Not Defined" 64491 "Not Defined" 64490 "Not Defined" 64489 "Not Defined" 64488 "Not Defined" 64487 "Not Defined" 64486 "Not Defined" 64485 "Not Defined" 64484 "Not Defined" 64483 "Not Defined" 64482 "Not Defined" 64481 "Not Defined" 64480 "Not Defined" 64479 "Not Defined" 64478 "Not Defined" 64477 "Not Defined" 64476 "Not Defined" 64475 "Not Defined" 64474 "Not Defined" 64473 "Not Defined" 64472 "Not Defined" 64471 "Not Defined" 64470 "Not Defined" 64469 "Not Defined" 64468 "Not Defined" 64467 "Not Defined" 64466 "Not Defined" 64465 "Not Defined" 64464 "Not Defined" 64463 "Not Defined" 64462 "Not Defined" 64461 "Not Defined" 64460 "Not Defined" 64459 "Not Defined" 64458 "Not Defined" 64457 "Not Defined" 64456 "Not Defined" 64455 "Not Defined" 64454 "Not Defined" 64453 "Not Defined" 64452 "Not Defined" 64451 "Not Defined" 64450 "Not Defined" 64449 "Not Defined" 64448 "Not Defined" 64447 "Not Defined" 64446 "Not Defined" 64445 "Not Defined" 64444 "Not Defined" 64443 "Not Defined" 64442 "Not Defined" 64441 "Not Defined" 64440 "Not Defined" 64439 "Not Defined" 64438 "Not Defined" 64437 "Not Defined" 64436 "Not Defined" 64435 "Not Defined" 64434 "Not Defined" 64433 "Not Defined" 64432 "Not Defined" 64431 "Not Defined" 64430 "Not Defined" 64429 "Not Defined" 64428 "Not Defined" 64427 "Not Defined" 64426 "Not Defined" 64425 "Not Defined" 64424 "Not Defined" 64423 "Not Defined" 64422 "Not Defined" 64421 "Not Defined" 64420 "Not Defined" 64419 "Not Defined" 64418 "Not Defined" 64417 "Not Defined" 64416 "Not Defined" 64415 "Not Defined" 64414 "Not Defined" 64413 "Not Defined" 64412 "Not Defined" 64411 "Not Defined" 64410 "Not Defined" 64409 "Not Defined" 64408 "Not Defined" 64407 "Not Defined" 64406 "Not Defined" 64405 "Not Defined" 64404 "Not Defined" 64403 "Not Defined" 64402 "Not Defined" 64401 "Not Defined" 64400 "Not Defined" 64399 "Not Defined" 64398 "Not Defined" 64397 "Not Defined" 64396 "Not Defined" 64395 "Not Defined" 64394 "Not Defined" 64393 "Not Defined" 64392 "Not Defined" 64391 "Not Defined" 64390 "Not Defined" 64389 "Not Defined" 64388 "Not Defined" 64387 "Not Defined" 64386 "Not Defined" 64385 "Not Defined" 64384 "Not Defined" 64383 "Not Defined" 64382 "Not Defined" 64381 "Not Defined" 64380 "Not Defined" 64379 "Not Defined" 64378 "Not Defined" 64377 "Not Defined" 64376 "Not Defined" 64375 "Not Defined" 64374 "Not Defined" 64373 "Not Defined" 64372 "Not Defined" 64371 "Not Defined" 64370 "Not Defined" 64369 "Not Defined" 64368 "Not Defined" 64367 "Not Defined" 64366 "Not Defined" 64365 "Not Defined" 64364 "Not Defined" 64363 "Not Defined" 64362 "Not Defined" 64361 "Not Defined" 64360 "Not Defined" 64359 "Not Defined" 64358 "Not Defined" 64357 "Not Defined" 64356 "Not Defined" 64355 "Not Defined" 64354 "Not Defined" 64353 "Not Defined" 64352 "Not Defined" 64351 "Not Defined" 64350 "Not Defined" 64349 "Not Defined" 64348 "Not Defined" 64347 "Not Defined" 64346 "Not Defined" 64345 "Not Defined" 64344 "Not Defined" 64343 "Not Defined" 64342 "Not Defined" 64341 "Not Defined" 64340 "Not Defined" 64339 "Not Defined" 64338 "Not Defined" 64337 "Not Defined" 64336 "Not Defined" 64335 "Not Defined" 64334 "Not Defined" 64333 "Not Defined" 64332 "Not Defined" 64331 "Not Defined" 64330 "Not Defined" 64329 "Not Defined" 64328 "Not Defined" 64327 "Not Defined" 64326 "Not Defined" 64325 "Not Defined" 64324 "Not Defined" 64323 "Not Defined" 64322 "Not Defined" 64321 "Not Defined" 64320 "Not Defined" 64319 "Not Defined" 64318 "Not Defined" 64317 "Not Defined" 64316 "Not Defined" 64315 "Not Defined" 64314 "Not Defined" 64313 "Not Defined" 64312 "Not Defined" 64311 "Not Defined" 64310 "Not Defined" 64309 "Not Defined" 64308 "Not Defined" 64307 "Not Defined" 64306 "Not Defined" 64305 "Not Defined" 64304 "Not Defined" 64303 "Not Defined" 64302 "Not Defined" 64301 "Not Defined" 64300 "Not Defined" 64299 "Not Defined" 64298 "Not Defined" 64297 "Not Defined" 64296 "Not Defined" 64295 "Not Defined" 64294 "Not Defined" 64293 "Not Defined" 64292 "Not Defined" 64291 "Not Defined" 64290 "Not Defined" 64289 "Not Defined" 64288 "Not Defined" 64287 "Not Defined" 64286 "Not Defined" 64285 "Not Defined" 64284 "Not Defined" 64283 "Not Defined" 64282 "Not Defined" 64281 "Not Defined" 64280 "Not Defined" 64279 "Not Defined" 64278 "Not Defined" 64277 "Not Defined" 64276 "Not Defined" 64275 "Not Defined" 64274 "Not Defined" 64273 "Not Defined" 64272 "Not Defined" 64271 "Not Defined" 64270 "Not Defined" 64269 "Not Defined" 64268 "Not Defined" 64267 "Not Defined" 64266 "Not Defined" 64265 "Not Defined" 64264 "Not Defined" 64263 "Not Defined" 64262 "Not Defined" 64261 "Not Defined" 64260 "Not Defined" 64259 "Not Defined" 64258 "Not Defined" 64257 "Not Defined" 64256 "Not Defined" ;
VAL_TABLE_ SLO_Values 255 "High Output status not available" 254 "High Output status not available" 253 "High Output status not available" 252 "High Output status not available" 251 "High Output status not available" 250 "High Output status not available" 249 "High Output status not available" 248 "High Output status not available" 247 "High Output status not available" 246 "High Output status not available" 245 "High Output status not available" 244 "High Output status not available" 243 "High Output status not available" 242 "High Output status not available" 241 "High Output status not available" 240 "High Output status not available" 239 "Not Defined" 238 "Not Defined" 237 "Not Defined" 236 "Not Defined" 235 "Not Defined" 234 "Not Defined" 233 "Not Defined" 232 "Not Defined" 231 "Not Defined" 230 "Not Defined" 229 "Not Defined" 228 "Not Defined" 227 "Not Defined" 226 "Not Defined" 225 "Not Defined" 224 "Not Defined" 223 "Not Defined" 222 "Not Defined" 221 "Not Defined" 220 "Not Defined" 219 "Not Defined" 218 "Not Defined" 217 "Not Defined" 216 "Not Defined" 215 "Not Defined" 214 "Not Defined" 213 "Not Defined" 212 "Not Defined" 211 "Not Defined" 210 "Not Defined" 209 "Not Defined" 208 "Not Defined" 207 "Not Defined" 206 "Not Defined" 205 "Not Defined" 204 "Not Defined" 203 "Not Defined" 202 "Not Defined" 201 "Not Defined" 200 "Not Defined" 199 "Not Defined" 198 "Not Defined" 197 "Not Defined" 196 "Not Defined" 195 "Not Defined" 194 "Not Defined" 193 "Not Defined" 192 "Not Defined" 191 "Not Defined" 190 "Not Defined" 189 "Not Defined" 188 "Not Defined" 187 "Not Defined" 186 "Not Defined" 185 "Not Defined" 184 "Not Defined" 183 "Not Defined" 182 "Not Defined" 181 "Not Defined" 180 "Not Defined" 179 "Not Defined" 178 "Not Defined" 177 "Not Defined" 176 "Not Defined" 175 "Not Defined" 174 "Not Defined" 173 "Not Defined" 172 "Not Defined" 171 "Not Defined" 170 "Not Defined" 169 "Not Defined" 168 "Not Defined" 167 "Not Defined" 166 "Not Defined" 165 "Not Defined" 164 "Not Defined" 163 "Not Defined" 162 "Not Defined" 161 "Not Defined" 160 "Not Defined" 159 "Not Defined" 158 "Not Defined" 157 "Not Defined" 156 "Not Defined" 155 "Not Defined" 154 "Not Defined" 153 "Not Defined" 152 "Not Defined" 151 "Not Defined" 150 "Not Defined" 149 "Not Defined" 148 "Not Defined" 147 "Not Defined" 146 "Not Defined" 145 "Not Defined" 144 "Not Defined" 143 "Not Defined" 142 "Not Defined" 141 "Not Defined" 140 "Not Defined" 139 "Not Defined" 138 "Not Defined" 137 "Not Defined" 136 "Not Defined" 135 "Not Defined" 134 "Not Defined" 133 "Not Defined" 132 "Not Defined" 131 "Not Defined" 130 "Not Defined" 129 "Not Defined" 128 "Not Defined" 127 "Not Defined" 126 "Not Defined" 125 "Not Defined" 124 "Not Defined" 123 "Not Defined" 122 "Not Defined" 121 "Not Defined" 120 "Not Defined" 119 "Not Defined" 118 "Not Defined" 117 "Not Defined" 116 "Not Defined" 115 "Not Defined" 114 "Not Defined" 113 "Not Defined" 112 "Not Defined" 111 "Not Defined" 110 "Not Defined" 109 "Not Defined" 108 "Not Defined" 107 "Not Defined" 106 "Not Defined" 105 "Not Defined" 104 "Not Defined" 103 "Not Defined" 102 "Not Defined" 101 "Not Defined" 100 "Not Defined" 99 "Not Defined" 98 "Not Defined" 97 "Not Defined" 96 "Not Defined" 95 "Not Defined" 94 "Not Defined" 93 "Not Defined" 92 "Not Defined" 91 "Not Defined" 90 "Not Defined" 89 "Not Defined" 88 "Not Defined" 87 "Not Defined" 86 "Not Defined" 85 "Not Defined" 84 "Not Defined" 83 "Not Defined" 82 "Not Defined" 81 "Not Defined" 80 "Not Defined" 79 "Not Defined" 78 "Not Defined" 77 "Not Defined" 76 "Not Defined" 75 "Not Defined" 74 "Not Defined" 73 "Not Defined" 72 "Not Defined" 71 "Not Defined" 70 "Not Defined" 69 "Not Defined" 68 "Not Defined" 67 "Not Defined" 66 "Not Defined" 65 "Not Defined" 64 "Not Defined" 63 "Not Defined" 62 "Not Defined" 61 "Not Defined" 60 "Not Defined" 59 "Not Defined" 58 "Not Defined" 57 "Not Defined" 56 "Not Defined" 55 "Not Defined" 54 "Not Defined" 53 "Not Defined" 52 "Not Defined" 51 "Not Defined" 50 "Not Defined" 49 "Not Defined" 48 "Not Defined" 47 "Not Defined" 46 "Not Defined" 45 "Not Defined" 44 "Not Defined" 43 "Not Defined" 42 "Not Defined" 41 "Not Defined" 40 "Not Defined" 39 "Not Defined" 38 "Not Defined" 37 "Not Defined" 36 "Not Defined" 35 "Not Defined" 34 "Not Defined" 33 "High Output On Status Not Define" 32 "High Output Off Status Not Defin" 31 "Not Defined" 30 "Not Defined" 29 "Not Defined" 28 "Not Defined" 27 "Not Defined" 26 "Not Defined" 25 "Not Defined" 24 "Not Defined" 23 "Not Defined" 22 "Not Defined" 21 "Not Defined" 20 "Not Defined" 19 "Not Defined" 18 "Not Defined" 17 "High Output In Status Nok" 16 "High Output Off Status Nok" 15 "High Output Not Available" 14 "Not Defined" 13 "Not Defined" 12 "Not Defined" 11 "Not Defined" 10 "Not Defined" 9 "Not Defined" 8 "Not Defined" 7 "Not Defined" 6 "Not Defined" 5 "Not Defined" 4 "Not Defined" 3 "Not Defined" 2 "Not Defined" 1 "High Output ON Status Ok" 0 "High Output Off Status Ok" ;
VAL_TABLE_ SHO_Values 255 "High Output status not available" 254 "High Output status not available" 253 "High Output status not available" 252 "High Output status not available" 251 "High Output status not available" 250 "High Output status not available" 249 "High Output status not available" 248 "High Output status not available" 247 "High Output status not available" 246 "High Output status not available" 245 "High Output status not available" 244 "High Output status not available" 243 "High Output status not available" 242 "High Output status not available" 241 "High Output status not available" 240 "High Output status not available" 239 "Not Defined" 238 "Not Defined" 237 "Not Defined" 236 "Not Defined" 235 "Not Defined" 234 "Not Defined" 233 "Not Defined" 232 "Not Defined" 231 "Not Defined" 230 "Not Defined" 229 "Not Defined" 228 "Not Defined" 227 "Not Defined" 226 "Not Defined" 225 "Not Defined" 224 "Not Defined" 223 "Not Defined" 222 "Not Defined" 221 "Not Defined" 220 "Not Defined" 219 "Not Defined" 218 "Not Defined" 217 "Not Defined" 216 "Not Defined" 215 "Not Defined" 214 "Not Defined" 213 "Not Defined" 212 "Not Defined" 211 "Not Defined" 210 "Not Defined" 209 "Not Defined" 208 "Not Defined" 207 "Not Defined" 206 "Not Defined" 205 "Not Defined" 204 "Not Defined" 203 "Not Defined" 202 "Not Defined" 201 "Not Defined" 200 "Not Defined" 199 "Not Defined" 198 "Not Defined" 197 "Not Defined" 196 "Not Defined" 195 "Not Defined" 194 "Not Defined" 193 "Not Defined" 192 "Not Defined" 191 "Not Defined" 190 "Not Defined" 189 "Not Defined" 188 "Not Defined" 187 "Not Defined" 186 "Not Defined" 185 "Not Defined" 184 "Not Defined" 183 "Not Defined" 182 "Not Defined" 181 "Not Defined" 180 "Not Defined" 179 "Not Defined" 178 "Not Defined" 177 "Not Defined" 176 "Not Defined" 175 "Not Defined" 174 "Not Defined" 173 "Not Defined" 172 "Not Defined" 171 "Not Defined" 170 "Not Defined" 169 "Not Defined" 168 "Not Defined" 167 "Not Defined" 166 "Not Defined" 165 "Not Defined" 164 "Not Defined" 163 "Not Defined" 162 "Not Defined" 161 "Not Defined" 160 "Not Defined" 159 "Not Defined" 158 "Not Defined" 157 "Not Defined" 156 "Not Defined" 155 "Not Defined" 154 "Not Defined" 153 "Not Defined" 152 "Not Defined" 151 "Not Defined" 150 "Not Defined" 149 "Not Defined" 148 "Not Defined" 147 "Not Defined" 146 "Not Defined" 145 "Not Defined" 144 "Not Defined" 143 "Not Defined" 142 "Not Defined" 141 "Not Defined" 140 "Not Defined" 139 "Not Defined" 138 "Not Defined" 137 "Not Defined" 136 "Not Defined" 135 "Not Defined" 134 "Not Defined" 133 "Not Defined" 132 "Not Defined" 131 "Not Defined" 130 "Not Defined" 129 "Not Defined" 128 "Not Defined" 127 "Not Defined" 126 "Not Defined" 125 "Not Defined" 124 "Not Defined" 123 "Not Defined" 122 "Not Defined" 121 "Not Defined" 120 "Not Defined" 119 "Not Defined" 118 "Not Defined" 117 "Not Defined" 116 "Not Defined" 115 "Not Defined" 114 "Not Defined" 113 "Not Defined" 112 "Not Defined" 111 "Not Defined" 110 "Not Defined" 109 "Not Defined" 108 "Not Defined" 107 "Not Defined" 106 "Not Defined" 105 "Not Defined" 104 "Not Defined" 103 "Not Defined" 102 "Not Defined" 101 "Not Defined" 100 "Not Defined" 99 "Not Defined" 98 "Not Defined" 97 "Not Defined" 96 "Not Defined" 95 "Not Defined" 94 "Not Defined" 93 "Not Defined" 92 "Not Defined" 91 "Not Defined" 90 "Not Defined" 89 "Not Defined" 88 "Not Defined" 87 "Not Defined" 86 "Not Defined" 85 "Not Defined" 84 "Not Defined" 83 "Not Defined" 82 "Not Defined" 81 "Not Defined" 80 "Not Defined" 79 "Not Defined" 78 "Not Defined" 77 "Not Defined" 76 "Not Defined" 75 "Not Defined" 74 "Not Defined" 73 "Not Defined" 72 "Not Defined" 71 "Not Defined" 70 "Not Defined" 69 "Not Defined" 68 "Not Defined" 67 "Not Defined" 66 "Not Defined" 65 "Not Defined" 64 "Not Defined" 63 "Not Defined" 62 "Not Defined" 61 "Not Defined" 60 "Not Defined" 59 "Not Defined" 58 "Not Defined" 57 "Not Defined" 56 "Not Defined" 55 "Not Defined" 54 "Not Defined" 53 "Not Defined" 52 "Not Defined" 51 "Not Defined" 50 "Not Defined" 49 "Not Defined" 48 "Not Defined" 47 "Not Defined" 46 "Not Defined" 45 "Not Defined" 44 "Not Defined" 43 "Not Defined" 42 "Not Defined" 41 "Not Defined" 40 "Not Defined" 39 "Not Defined" 38 "Not Defined" 37 "Not Defined" 36 "Not Defined" 35 "Not Defined" 34 "Not Defined" 33 "High Output On Status Not Define" 32 "High Output Off Status Not Defin" 31 "Not Defined" 30 "Not Defined" 29 "Not Defined" 28 "Not Defined" 27 "Not Defined" 26 "Not Defined" 25 "Not Defined" 24 "Not Defined" 23 "Not Defined" 22 "Not Defined" 21 "Not Defined" 20 "Not Defined" 19 "Not Defined" 18 "Not Defined" 17 "High Output In Status Nok" 16 "High Output Off Status Nok" 15 "High Output Not Available" 14 "Not Defined" 13 "Not Defined" 12 "Not Defined" 11 "Not Defined" 10 "Not Defined" 9 "Not Defined" 8 "Not Defined" 7 "Not Defined" 6 "Not Defined" 5 "Not Defined" 4 "Not Defined" 3 "Not Defined" 2 "Not Defined" 1 "High Output ON Status Ok" 0 "High Output Off Status Ok" ;
VAL_TABLE_ RMO_Values 255 "Signal Not Available" 254 "Not Defined" 253 "Not Defined" 252 "Not Defined" 251 "Not Defined" 250 "Not Defined" 249 "Not Defined" 248 "Not Defined" 247 "Not Defined" 246 "Not Defined" 245 "Not Defined" 244 "Not Defined" 243 "Not Defined" 242 "Not Defined" 241 "Not Defined" ;
VAL_TABLE_ CMO_Values 65535 "Signal Not Available" 64510 "Not Defined" 64509 "Not Defined" 64508 "Not Defined" 64507 "Not Defined" 64506 "Not Defined" 64505 "Not Defined" 64504 "Not Defined" 64503 "Not Defined" 64502 "Not Defined" 64501 "Not Defined" 64500 "Not Defined" 64499 "Not Defined" 64498 "Not Defined" 64497 "Not Defined" 64496 "Not Defined" 64495 "Not Defined" 64494 "Not Defined" 64493 "Not Defined" 64492 "Not Defined" 64491 "Not Defined" 64490 "Not Defined" 64489 "Not Defined" 64488 "Not Defined" 64487 "Not Defined" 64486 "Not Defined" 64485 "Not Defined" 64484 "Not Defined" 64483 "Not Defined" 64482 "Not Defined" 64481 "Not Defined" 64480 "Not Defined" 64479 "Not Defined" 64478 "Not Defined" 64477 "Not Defined" 64476 "Not Defined" 64475 "Not Defined" 64474 "Not Defined" 64473 "Not Defined" 64472 "Not Defined" 64471 "Not Defined" 64470 "Not Defined" 64469 "Not Defined" 64468 "Not Defined" 64467 "Not Defined" 64466 "Not Defined" 64465 "Not Defined" 64464 "Not Defined" 64463 "Not Defined" 64462 "Not Defined" 64461 "Not Defined" 64460 "Not Defined" 64459 "Not Defined" 64458 "Not Defined" 64457 "Not Defined" 64456 "Not Defined" 64455 "Not Defined" 64454 "Not Defined" 64453 "Not Defined" 64452 "Not Defined" 64451 "Not Defined" 64450 "Not Defined" 64449 "Not Defined" 64448 "Not Defined" 64447 "Not Defined" 64446 "Not Defined" 64445 "Not Defined" 64444 "Not Defined" 64443 "Not Defined" 64442 "Not Defined" 64441 "Not Defined" 64440 "Not Defined" 64439 "Not Defined" 64438 "Not Defined" 64437 "Not Defined" 64436 "Not Defined" 64435 "Not Defined" 64434 "Not Defined" 64433 "Not Defined" 64432 "Not Defined" 64431 "Not Defined" 64430 "Not Defined" 64429 "Not Defined" 64428 "Not Defined" 64427 "Not Defined" 64426 "Not Defined" 64425 "Not Defined" 64424 "Not Defined" 64423 "Not Defined" 64422 "Not Defined" 64421 "Not Defined" 64420 "Not Defined" 64419 "Not Defined" 64418 "Not Defined" 64417 "Not Defined" 64416 "Not Defined" 64415 "Not Defined" 64414 "Not Defined" 64413 "Not Defined" 64412 "Not Defined" 64411 "Not Defined" 64410 "Not Defined" 64409 "Not Defined" 64408 "Not Defined" 64407 "Not Defined" 64406 "Not Defined" 64405 "Not Defined" 64404 "Not Defined" 64403 "Not Defined" 64402 "Not Defined" 64401 "Not Defined" 64400 "Not Defined" 64399 "Not Defined" 64398 "Not Defined" 64397 "Not Defined" 64396 "Not Defined" 64395 "Not Defined" 64394 "Not Defined" 64393 "Not Defined" 64392 "Not Defined" 64391 "Not Defined" 64390 "Not Defined" 64389 "Not Defined" 64388 "Not Defined" 64387 "Not Defined" 64386 "Not Defined" 64385 "Not Defined" 64384 "Not Defined" 64383 "Not Defined" 64382 "Not Defined" 64381 "Not Defined" 64380 "Not Defined" 64379 "Not Defined" 64378 "Not Defined" 64377 "Not Defined" 64376 "Not Defined" 64375 "Not Defined" 64374 "Not Defined" 64373 "Not Defined" 64372 "Not Defined" 64371 "Not Defined" 64370 "Not Defined" 64369 "Not Defined" 64368 "Not Defined" 64367 "Not Defined" 64366 "Not Defined" 64365 "Not Defined" 64364 "Not Defined" 64363 "Not Defined" 64362 "Not Defined" 64361 "Not Defined" 64360 "Not Defined" 64359 "Not Defined" 64358 "Not Defined" 64357 "Not Defined" 64356 "Not Defined" 64355 "Not Defined" 64354 "Not Defined" 64353 "Not Defined" 64352 "Not Defined" 64351 "Not Defined" 64350 "Not Defined" 64349 "Not Defined" 64348 "Not Defined" 64347 "Not Defined" 64346 "Not Defined" 64345 "Not Defined" 64344 "Not Defined" 64343 "Not Defined" 64342 "Not Defined" 64341 "Not Defined" 64340 "Not Defined" 64339 "Not Defined" 64338 "Not Defined" 64337 "Not Defined" 64336 "Not Defined" 64335 "Not Defined" 64334 "Not Defined" 64333 "Not Defined" 64332 "Not Defined" 64331 "Not Defined" 64330 "Not Defined" 64329 "Not Defined" 64328 "Not Defined" 64327 "Not Defined" 64326 "Not Defined" 64325 "Not Defined" 64324 "Not Defined" 64323 "Not Defined" 64322 "Not Defined" 64321 "Not Defined" 64320 "Not Defined" 64319 "Not Defined" 64318 "Not Defined" 64317 "Not Defined" 64316 "Not Defined" 64315 "Not Defined" 64314 "Not Defined" 64313 "Not Defined" 64312 "Not Defined" 64311 "Not Defined" 64310 "Not Defined" 64309 "Not Defined" 64308 "Not Defined" 64307 "Not Defined" 64306 "Not Defined" 64305 "Not Defined" 64304 "Not Defined" 64303 "Not Defined" 64302 "Not Defined" 64301 "Not Defined" 64300 "Not Defined" 64299 "Not Defined" 64298 "Not Defined" 64297 "Not Defined" 64296 "Not Defined" 64295 "Not Defined" 64294 "Not Defined" 64293 "Not Defined" 64292 "Not Defined" 64291 "Not Defined" 64290 "Not Defined" 64289 "Not Defined" 64288 "Not Defined" 64287 "Not Defined" 64286 "Not Defined" 64285 "Not Defined" 64284 "Not Defined" 64283 "Not Defined" 64282 "Not Defined" 64281 "Not Defined" 64280 "Not Defined" 64279 "Not Defined" 64278 "Not Defined" 64277 "Not Defined" 64276 "Not Defined" 64275 "Not Defined" 64274 "Not Defined" 64273 "Not Defined" 64272 "Not Defined" 64271 "Not Defined" 64270 "Not Defined" 64269 "Not Defined" 64268 "Not Defined" 64267 "Not Defined" 64266 "Not Defined" 64265 "Not Defined" 64264 "Not Defined" 64263 "Not Defined" 64262 "Not Defined" 64261 "Not Defined" 64260 "Not Defined" 64259 "Not Defined" 64258 "Not Defined" 64257 "Not Defined" 64256 "Not Defined" ;

BO_ 3221225472 VECTOR__INDEPENDENT_SIG_MSG: 0 Vector__XXX
 SG_ DAM_COM_DataIdByte : 0|8@1+ (1,0) [0|0] "" Vector__XXX
 SG_ DAM_COM_Cmd : 0|8@1+ (1,0) [0|0] "" Vector__XXX
 SG_ DAM_Soll : 0|16@1+ (0.00390625,-125) [-125|125] "grd" Vector__XXX
 SG_ DAM_FrontAngle : 0|16@1+ (0.00390625,-125) [-125|125] "" Vector__XXX
 SG_ DAM_SeqCounter : 0|8@1+ (1,0) [0|0] "" Vector__XXX
 SG_ ETSD3_DamMasterDiag : 0|8@1+ (1,0) [0|0] "" Vector__XXX
 SG_ ETSD3_ManualControlCan : 0|8@1+ (1,0) [0|0] "" Vector__XXX
 SG_ ETSD3_ManualSteerMotorOnCombined : 0|8@1+ (1,0) [0|0] "" Vector__XXX
 SG_ ETSD3_DiagSteerRequest : 0|8@1+ (1,0) [0|0] "" Vector__XXX
 SG_ ETSS_ExtPumpUseActive : 0|4@1+ (1,0) [0|0] "" Vector__XXX
 SG_ ETSS_AlarmOilLevel : 0|4@1+ (1,0) [0|0] "" Vector__XXX
 SG_ ETSS_CentringState : 0|1@1+ (1,0) [0|0] "" Vector__XXX

BO_ 2147549064 EtsDataMessage5: 8 Vector__XXX
 SG_ ETSD5_Py2Pressure : 16|16@1+ (0.02,0) [0|0] "Bar" Vector__XXX
 SG_ ETSD5_Py2Cofa : 0|16@1+ (1,0) [0|0] "" Vector__XXX

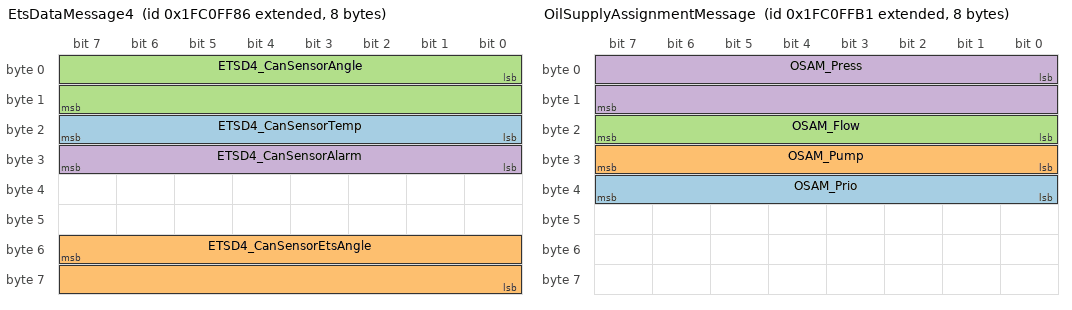
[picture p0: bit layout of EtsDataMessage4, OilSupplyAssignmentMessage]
BO_ 2680225670 EtsDataMessage4: 8 Vector__XXX
 SG_ ETSD4_CanSensorTemp : 16|8@1+ (1,-40) [-40|210] "grd/C" Vector__XXX
 SG_ ETSD4_CanSensorEtsAngle : 55|16@0+ (0.125,-64) [-64|0] "Grd" Vector__XXX
 SG_ ETSD4_CanSensorAngle : 0|16@1+ (0.0078125,-200) [-200|301.99] "Grd" Vector__XXX
 SG_ ETSD4_CanSensorAlarm : 24|8@1+ (1,0) [0|0] "" Vector__XXX

BO_ 2680225713 OilSupplyAssignmentMessage: 8 Vector__XXX
 SG_ OSAM_Prio : 32|8@1+ (1,0) [0|0] "" Vector__XXX
 SG_ OSAM_Pump : 24|8@1+ (1,0) [0|0] "On/Off" Vector__XXX
 SG_ OSAM_Flow : 16|8@1+ (1,0) [0|0] "pct" Vector__XXX
 SG_ OSAM_Press : 0|16@1+ (0.02,0) [0|0] "bar" Vector__XXX

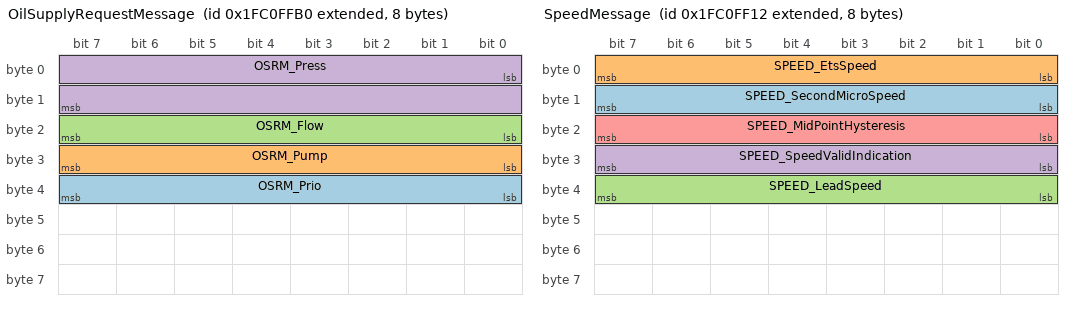
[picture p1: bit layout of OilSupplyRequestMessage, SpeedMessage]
BO_ 2680225712 OilSupplyRequestMessage: 8 Vector__XXX
 SG_ OSRM_Prio : 32|8@1+ (1,0) [0|0] "" Vector__XXX
 SG_ OSRM_Pump : 24|8@1+ (1,0) [0|0] "On/Off" Vector__XXX
 SG_ OSRM_Flow : 16|8@1+ (1,0) [0|0] "pct" Vector__XXX
 SG_ OSRM_Press : 0|16@1+ (0.02,0) [0|0] "bar" Vector__XXX

BO_ 2680225554 SpeedMessage: 8 Vector__XXX
 SG_ SPEED_SecondMicroSpeed : 8|8@1+ (1,0) [0|250] "km/h" Vector__XXX
 SG_ SPEED_EtsSpeed : 0|8@1+ (1,0) [0|250] "km/h" Vector__XXX
 SG_ SPEED_LeadSpeed : 32|8@1- (1,0) [0|0] "" Vector__XXX
 SG_ SPEED_SpeedValidIndication : 24|8@1- (1,0) [0|0] "" Vector__XXX
 SG_ SPEED_MidPointHysteresis : 16|8@1- (1,0) [0|0] "" Vector__XXX

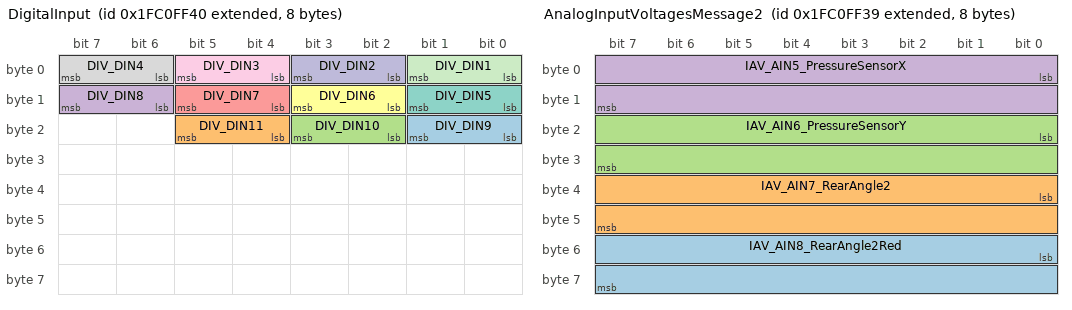
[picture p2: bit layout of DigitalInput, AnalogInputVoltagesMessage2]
BO_ 2680225600 DigitalInput: 8 Vector__XXX
 SG_ DIV_DIN9 : 16|2@1+ (1,0) [0|0] "" Vector__XXX
 SG_ DIV_DIN11 : 20|2@1+ (1,0) [0|0] "" Vector__XXX
 SG_ DIV_DIN10 : 18|2@1+ (1,0) [0|0] "" Vector__XXX
 SG_ DIV_DIN8 : 14|2@1+ (1,0) [0|0] "" Vector__XXX
 SG_ DIV_DIN7 : 12|2@1+ (1,0) [0|0] "" Vector__XXX
 SG_ DIV_DIN6 : 10|2@1+ (1,0) [0|0] "" Vector__XXX
 SG_ DIV_DIN5 : 8|2@1+ (1,0) [0|0] "" Vector__XXX
 SG_ DIV_DIN4 : 6|2@1+ (1,0) [0|0] "" Vector__XXX
 SG_ DIV_DIN3 : 4|2@1+ (1,0) [0|0] "" Vector__XXX
 SG_ DIV_DIN2 : 2|2@1+ (1,0) [0|0] "" Vector__XXX
 SG_ DIV_DIN1 : 0|2@1+ (1,0) [0|0] "" Vector__XXX

BO_ 2680225593 AnalogInputVoltagesMessage2: 8 Vector__XXX
 SG_ IAV_AIN8_RearAngle2Red : 48|16@1+ (0.01,0) [0|642.55] "V" Vector__XXX
 SG_ IAV_AIN7_RearAngle2 : 32|16@1+ (0.01,0) [0|642.55] "V" Vector__XXX
 SG_ IAV_AIN6_PressureSensorY : 16|16@1+ (0.01,0) [0|642.55] "V" Vector__XXX
 SG_ IAV_AIN5_PressureSensorX : 0|16@1+ (0.01,0) [0|642.55] "V" Vector__XXX

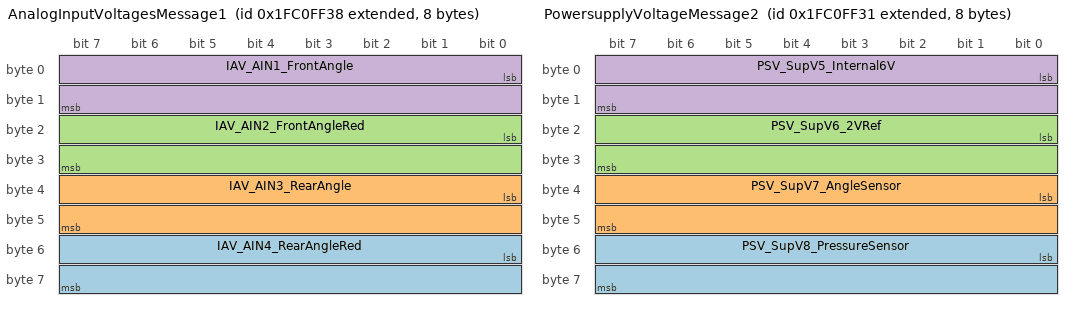
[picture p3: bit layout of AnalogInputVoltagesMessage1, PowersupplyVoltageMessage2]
BO_ 2680225592 AnalogInputVoltagesMessage1: 8 Vector__XXX
 SG_ IAV_AIN4_RearAngleRed : 48|16@1+ (0.01,0) [0|642.55] "V" Vector__XXX
 SG_ IAV_AIN3_RearAngle : 32|16@1+ (0.01,0) [0|642.55] "V" Vector__XXX
 SG_ IAV_AIN2_FrontAngleRed : 16|16@1+ (0.01,0) [0|642.55] "V" Vector__XXX
 SG_ IAV_AIN1_FrontAngle : 0|16@1+ (0.01,0) [0|642.55] "V" Vector__XXX

BO_ 2680225585 PowersupplyVoltageMessage2: 8 Vector__XXX
 SG_ PSV_SupV8_PressureSensor : 48|16@1+ (0.01,0) [0|642.55] "V" Vector__XXX
 SG_ PSV_SupV7_AngleSensor : 32|16@1+ (0.01,0) [0|642.55] "V" Vector__XXX
 SG_ PSV_SupV6_2VRef : 16|16@1+ (0.01,0) [0|642.55] "V" Vector__XXX
 SG_ PSV_SupV5_Internal6V : 0|16@1+ (0.01,0) [0|642.55] "V" Vector__XXX

CM_ BO_ 3221225472 "This is a message for not used signals, created by Vector CANdb++ DBC OLE DB Provider.";
BA_DEF_  "BusType" STRING ;
BA_DEF_  "J1939PGN" INT 0 1;
BA_DEF_DEF_  "BusType" "CAN";
BA_DEF_DEF_  "J1939PGN" 1;
VAL_ 3221225472 ETSD3_DiagSteerRequest 4 "Diag Don't Move" 3 "Diag Centre" 2 "Diag Steer Right" 1 "Diag Steer Left" 0 "Diag Inactive" ;
VAL_ 3221225472 ETSS_CentringState 1 "ETS System is Active or Passive " 0 "Centring Steering Axle bij Centr" ;
VAL_ 2147549064 ETSD5_Py2Pressure 65024 "Sensor Elektric Alarm" 64768 "Sensor Not Calibrated" ;
VAL_ 2680225554 SPEED_SecondMicroSpeed 255 "Signal not Available" 254 "not defined" 253 "not defined" 252 "not defined" 251 "not defined" ;
VAL_ 2680225554 SPEED_EtsSpeed 255 "Signal not Available" 254 "not defined" 253 "not defined" 252 "not defined" 251 "not defined" ;
VAL_ 2680225554 SPEED_LeadSpeed 3 "No Valid Speed Decrement" 2 "Lead Speed " 1 "Lead Speed 1" 0 "No Speed Selected" ;
VAL_ 2680225554 SPEED_SpeedValidIndication 4 "Two Reliable Speeds" 3 "One Reliable Speed" 2 "No Reliable Speed But Front Angl" 1 "No Reliable Speed" ;
VAL_ 2680225554 SPEED_MidPointHysteresis 1 "Additional MidPointHyst On" 0 "Additional MidPointHyst Off" ;
VAL_ 2680225600 DIV_DIN8 3 "Signal not Available" 2 "Failure/Incorrect Status" 1 "Input is High" 0 "Input is Low" ;
VAL_ 2680225600 DIV_DIN7 3 "Signal not Available" 2 "Failure/Incorrect Status" 1 "Input is High" 0 "Input is Low" ;
VAL_ 2680225600 DIV_DIN6 3 "Signal not Available" 2 "Failure/Incorrect Status" 1 "Input is High" 0 "Input is Low" ;
VAL_ 2680225600 DIV_DIN5 3 "Signal not Available" 2 "Failure/Incorrect Status" 1 "Input is High" 0 "Input is Low" ;
VAL_ 2680225600 DIV_DIN4 3 "Signal not Available" 2 "Failure/Incorrect Status" 1 "Input is High" 0 "Input is Low" ;
VAL_ 2680225600 DIV_DIN3 3 "Signal not Available" 2 "Failure/Incorrect Status" 1 "Input is High" 0 "Input is Low" ;
VAL_ 2680225600 DIV_DIN2 3 "Signal not Available" 2 "Failure/Incorrect Status" 1 "Input is High" 0 "Input is Low" ;
VAL_ 2680225600 DIV_DIN1 3 "Signal not Available" 2 "Failure/Incorrect Status" 1 "Input is High" 0 "Input is Low" ;
VAL_ 2680225593 IAV_AIN8_RearAngle2Red 65535 "Signal not available" 64510 "Not Defined" 64509 "Not Defined" 64508 "Not Defined" 64507 "Not Defined" 64506 "Not Defined" 64505 "Not Defined" 64504 "Not Defined" 64503 "Not Defined" 64502 "Not Defined" 64501 "Not Defined" 64500 "Not Defined" 64499 "Not Defined" 64498 "Not Defined" 64497 "Not Defined" 64496 "Not Defined" 64495 "Not Defined" 64494 "Not Defined" 64493 "Not Defined" 64492 "Not Defined" 64491 "Not Defined" 64490 "Not Defined" 64489 "Not Defined" 64488 "Not Defined" 64487 "Not Defined" 64486 "Not Defined" 64485 "Not Defined" 64484 "Not Defined" 64483 "Not Defined" 64482 "Not Defined" 64481 "Not Defined" 64480 "Not Defined" 64479 "Not Defined" 64478 "Not Defined" 64477 "Not Defined" 64476 "Not Defined" 64475 "Not Defined" 64474 "Not Defined" 64473 "Not Defined" 64472 "Not Defined" 64471 "Not Defined" 64470 "Not Defined" 64469 "Not Defined" 64468 "Not Defined" 64467 "Not Defined" 64466 "Not Defined" 64465 "Not Defined" 64464 "Not Defined" 64463 "Not Defined" 64462 "Not Defined" 64461 "Not Defined" 64460 "Not Defined" 64459 "Not Defined" 64458 "Not Defined" 64457 "Not Defined" 64456 "Not Defined" 64455 "Not Defined" 64454 "Not Defined" 64453 "Not Defined" 64452 "Not Defined" 64451 "Not Defined" 64450 "Not Defined" 64449 "Not Defined" 64448 "Not Defined" 64447 "Not Defined" 64446 "Not Defined" 64445 "Not Defined" 64444 "Not Defined" 64443 "Not Defined" 64442 "Not Defined" 64441 "Not Defined" 64440 "Not Defined" 64439 "Not Defined" 64438 "Not Defined" 64437 "Not Defined" 64436 "Not Defined" 64435 "Not Defined" 64434 "Not Defined" 64433 "Not Defined" 64432 "Not Defined" 64431 "Not Defined" 64430 "Not Defined" 64429 "Not Defined" 64428 "Not Defined" 64427 "Not Defined" 64426 "Not Defined" 64425 "Not Defined" 64424 "Not Defined" 64423 "Not Defined" 64422 "Not Defined" 64421 "Not Defined" 64420 "Not Defined" 64419 "Not Defined" 64418 "Not Defined" 64417 "Not Defined" 64416 "Not Defined" 64415 "Not Defined" 64414 "Not Defined" 64413 "Not Defined" 64412 "Not Defined" 64411 "Not Defined" 64410 "Not Defined" 64409 "Not Defined" 64408 "Not Defined" 64407 "Not Defined" 64406 "Not Defined" 64405 "Not Defined" 64404 "Not Defined" 64403 "Not Defined" 64402 "Not Defined" 64401 "Not Defined" 64400 "Not Defined" 64399 "Not Defined" 64398 "Not Defined" 64397 "Not Defined" 64396 "Not Defined" 64395 "Not Defined" 64394 "Not Defined" 64393 "Not Defined" 64392 "Not Defined" 64391 "Not Defined" 64390 "Not Defined" 64389 "Not Defined" 64388 "Not Defined" 64387 "Not Defined" 64386 "Not Defined" 64385 "Not Defined" 64384 "Not Defined" 64383 "Not Defined" 64382 "Not Defined" 64381 "Not Defined" 64380 "Not Defined" 64379 "Not Defined" 64378 "Not Defined" 64377 "Not Defined" 64376 "Not Defined" 64375 "Not Defined" 64374 "Not Defined" 64373 "Not Defined" 64372 "Not Defined" 64371 "Not Defined" 64370 "Not Defined" 64369 "Not Defined" 64368 "Not Defined" 64367 "Not Defined" 64366 "Not Defined" 64365 "Not Defined" 64364 "Not Defined" 64363 "Not Defined" 64362 "Not Defined" 64361 "Not Defined" 64360 "Not Defined" 64359 "Not Defined" 64358 "Not Defined" 64357 "Not Defined" 64356 "Not Defined" 64355 "Not Defined" 64354 "Not Defined" 64353 "Not Defined" 64352 "Not Defined" 64351 "Not Defined" 64350 "Not Defined" 64349 "Not Defined" 64348 "Not Defined" 64347 "Not Defined" 64346 "Not Defined" 64345 "Not Defined" 64344 "Not Defined" 64343 "Not Defined" 64342 "Not Defined" 64341 "Not Defined" 64340 "Not Defined" 64339 "Not Defined" 64338 "Not Defined" 64337 "Not Defined" 64336 "Not Defined" 64335 "Not Defined" 64334 "Not Defined" 64333 "Not Defined" 64332 "Not Defined" 64331 "Not Defined" 64330 "Not Defined" 64329 "Not Defined" 64328 "Not Defined" 64327 "Not Defined" 64326 "Not Defined" 64325 "Not Defined" 64324 "Not Defined" 64323 "Not Defined" 64322 "Not Defined" 64321 "Not Defined" 64320 "Not Defined" 64319 "Not Defined" 64318 "Not Defined" 64317 "Not Defined" 64316 "Not Defined" 64315 "Not Defined" 64314 "Not Defined" 64313 "Not Defined" 64312 "Not Defined" 64311 "Not Defined" 64310 "Not Defined" 64309 "Not Defined" 64308 "Not Defined" 64307 "Not Defined" 64306 "Not Defined" 64305 "Not Defined" 64304 "Not Defined" 64303 "Not Defined" 64302 "Not Defined" 64301 "Not Defined" 64300 "Not Defined" 64299 "Not Defined" 64298 "Not Defined" 64297 "Not Defined" 64296 "Not Defined" 64295 "Not Defined" 64294 "Not Defined" 64293 "Not Defined" 64292 "Not Defined" 64291 "Not Defined" 64290 "Not Defined" 64289 "Not Defined" 64288 "Not Defined" 64287 "Not Defined" 64286 "Not Defined" 64285 "Not Defined" 64284 "Not Defined" 64283 "Not Defined" 64282 "Not Defined" 64281 "Not Defined" 64280 "Not Defined" 64279 "Not Defined" 64278 "Not Defined" 64277 "Not Defined" 64276 "Not Defined" 64275 "Not Defined" 64274 "Not Defined" 64273 "Not Defined" 64272 "Not Defined" 64271 "Not Defined" 64270 "Not Defined" 64269 "Not Defined" 64268 "Not Defined" 64267 "Not Defined" 64266 "Not Defined" 64265 "Not Defined" 64264 "Not Defined" 64263 "Not Defined" 64262 "Not Defined" 64261 "Not Defined" 64260 "Not Defined" 64259 "Not Defined" 64258 "Not Defined" 64257 "Not Defined" 64256 "Not Defined" ;
VAL_ 2680225593 IAV_AIN7_RearAngle2 65535 "Signal not available" 64510 "Not Defined" 64509 "Not Defined" 64508 "Not Defined" 64507 "Not Defined" 64506 "Not Defined" 64505 "Not Defined" 64504 "Not Defined" 64503 "Not Defined" 64502 "Not Defined" 64501 "Not Defined" 64500 "Not Defined" 64499 "Not Defined" 64498 "Not Defined" 64497 "Not Defined" 64496 "Not Defined" 64495 "Not Defined" 64494 "Not Defined" 64493 "Not Defined" 64492 "Not Defined" 64491 "Not Defined" 64490 "Not Defined" 64489 "Not Defined" 64488 "Not Defined" 64487 "Not Defined" 64486 "Not Defined" 64485 "Not Defined" 64484 "Not Defined" 64483 "Not Defined" 64482 "Not Defined" 64481 "Not Defined" 64480 "Not Defined" 64479 "Not Defined" 64478 "Not Defined" 64477 "Not Defined" 64476 "Not Defined" 64475 "Not Defined" 64474 "Not Defined" 64473 "Not Defined" 64472 "Not Defined" 64471 "Not Defined" 64470 "Not Defined" 64469 "Not Defined" 64468 "Not Defined" 64467 "Not Defined" 64466 "Not Defined" 64465 "Not Defined" 64464 "Not Defined" 64463 "Not Defined" 64462 "Not Defined" 64461 "Not Defined" 64460 "Not Defined" 64459 "Not Defined" 64458 "Not Defined" 64457 "Not Defined" 64456 "Not Defined" 64455 "Not Defined" 64454 "Not Defined" 64453 "Not Defined" 64452 "Not Defined" 64451 "Not Defined" 64450 "Not Defined" 64449 "Not Defined" 64448 "Not Defined" 64447 "Not Defined" 64446 "Not Defined" 64445 "Not Defined" 64444 "Not Defined" 64443 "Not Defined" 64442 "Not Defined" 64441 "Not Defined" 64440 "Not Defined" 64439 "Not Defined" 64438 "Not Defined" 64437 "Not Defined" 64436 "Not Defined" 64435 "Not Defined" 64434 "Not Defined" 64433 "Not Defined" 64432 "Not Defined" 64431 "Not Defined" 64430 "Not Defined" 64429 "Not Defined" 64428 "Not Defined" 64427 "Not Defined" 64426 "Not Defined" 64425 "Not Defined" 64424 "Not Defined" 64423 "Not Defined" 64422 "Not Defined" 64421 "Not Defined" 64420 "Not Defined" 64419 "Not Defined" 64418 "Not Defined" 64417 "Not Defined" 64416 "Not Defined" 64415 "Not Defined" 64414 "Not Defined" 64413 "Not Defined" 64412 "Not Defined" 64411 "Not Defined" 64410 "Not Defined" 64409 "Not Defined" 64408 "Not Defined" 64407 "Not Defined" 64406 "Not Defined" 64405 "Not Defined" 64404 "Not Defined" 64403 "Not Defined" 64402 "Not Defined" 64401 "Not Defined" 64400 "Not Defined" 64399 "Not Defined" 64398 "Not Defined" 64397 "Not Defined" 64396 "Not Defined" 64395 "Not Defined" 64394 "Not Defined" 64393 "Not Defined" 64392 "Not Defined" 64391 "Not Defined" 64390 "Not Defined" 64389 "Not Defined" 64388 "Not Defined" 64387 "Not Defined" 64386 "Not Defined" 64385 "Not Defined" 64384 "Not Defined" 64383 "Not Defined" 64382 "Not Defined" 64381 "Not Defined" 64380 "Not Defined" 64379 "Not Defined" 64378 "Not Defined" 64377 "Not Defined" 64376 "Not Defined" 64375 "Not Defined" 64374 "Not Defined" 64373 "Not Defined" 64372 "Not Defined" 64371 "Not Defined" 64370 "Not Defined" 64369 "Not Defined" 64368 "Not Defined" 64367 "Not Defined" 64366 "Not Defined" 64365 "Not Defined" 64364 "Not Defined" 64363 "Not Defined" 64362 "Not Defined" 64361 "Not Defined" 64360 "Not Defined" 64359 "Not Defined" 64358 "Not Defined" 64357 "Not Defined" 64356 "Not Defined" 64355 "Not Defined" 64354 "Not Defined" 64353 "Not Defined" 64352 "Not Defined" 64351 "Not Defined" 64350 "Not Defined" 64349 "Not Defined" 64348 "Not Defined" 64347 "Not Defined" 64346 "Not Defined" 64345 "Not Defined" 64344 "Not Defined" 64343 "Not Defined" 64342 "Not Defined" 64341 "Not Defined" 64340 "Not Defined" 64339 "Not Defined" 64338 "Not Defined" 64337 "Not Defined" 64336 "Not Defined" 64335 "Not Defined" 64334 "Not Defined" 64333 "Not Defined" 64332 "Not Defined" 64331 "Not Defined" 64330 "Not Defined" 64329 "Not Defined" 64328 "Not Defined" 64327 "Not Defined" 64326 "Not Defined" 64325 "Not Defined" 64324 "Not Defined" 64323 "Not Defined" 64322 "Not Defined" 64321 "Not Defined" 64320 "Not Defined" 64319 "Not Defined" 64318 "Not Defined" 64317 "Not Defined" 64316 "Not Defined" 64315 "Not Defined" 64314 "Not Defined" 64313 "Not Defined" 64312 "Not Defined" 64311 "Not Defined" 64310 "Not Defined" 64309 "Not Defined" 64308 "Not Defined" 64307 "Not Defined" 64306 "Not Defined" 64305 "Not Defined" 64304 "Not Defined" 64303 "Not Defined" 64302 "Not Defined" 64301 "Not Defined" 64300 "Not Defined" 64299 "Not Defined" 64298 "Not Defined" 64297 "Not Defined" 64296 "Not Defined" 64295 "Not Defined" 64294 "Not Defined" 64293 "Not Defined" 64292 "Not Defined" 64291 "Not Defined" 64290 "Not Defined" 64289 "Not Defined" 64288 "Not Defined" 64287 "Not Defined" 64286 "Not Defined" 64285 "Not Defined" 64284 "Not Defined" 64283 "Not Defined" 64282 "Not Defined" 64281 "Not Defined" 64280 "Not Defined" 64279 "Not Defined" 64278 "Not Defined" 64277 "Not Defined" 64276 "Not Defined" 64275 "Not Defined" 64274 "Not Defined" 64273 "Not Defined" 64272 "Not Defined" 64271 "Not Defined" 64270 "Not Defined" 64269 "Not Defined" 64268 "Not Defined" 64267 "Not Defined" 64266 "Not Defined" 64265 "Not Defined" 64264 "Not Defined" 64263 "Not Defined" 64262 "Not Defined" 64261 "Not Defined" 64260 "Not Defined" 64259 "Not Defined" 64258 "Not Defined" 64257 "Not Defined" 64256 "Not Defined" ;
VAL_ 2680225593 IAV_AIN6_PressureSensorY 65535 "Signal not available" 64510 "Not Defined" 64509 "Not Defined" 64508 "Not Defined" 64507 "Not Defined" 64506 "Not Defined" 64505 "Not Defined" 64504 "Not Defined" 64503 "Not Defined" 64502 "Not Defined" 64501 "Not Defined" 64500 "Not Defined" 64499 "Not Defined" 64498 "Not Defined" 64497 "Not Defined" 64496 "Not Defined" 64495 "Not Defined" 64494 "Not Defined" 64493 "Not Defined" 64492 "Not Defined" 64491 "Not Defined" 64490 "Not Defined" 64489 "Not Defined" 64488 "Not Defined" 64487 "Not Defined" 64486 "Not Defined" 64485 "Not Defined" 64484 "Not Defined" 64483 "Not Defined" 64482 "Not Defined" 64481 "Not Defined" 64480 "Not Defined" 64479 "Not Defined" 64478 "Not Defined" 64477 "Not Defined" 64476 "Not Defined" 64475 "Not Defined" 64474 "Not Defined" 64473 "Not Defined" 64472 "Not Defined" 64471 "Not Defined" 64470 "Not Defined" 64469 "Not Defined" 64468 "Not Defined" 64467 "Not Defined" 64466 "Not Defined" 64465 "Not Defined" 64464 "Not Defined" 64463 "Not Defined" 64462 "Not Defined" 64461 "Not Defined" 64460 "Not Defined" 64459 "Not Defined" 64458 "Not Defined" 64457 "Not Defined" 64456 "Not Defined" 64455 "Not Defined" 64454 "Not Defined" 64453 "Not Defined" 64452 "Not Defined" 64451 "Not Defined" 64450 "Not Defined" 64449 "Not Defined" 64448 "Not Defined" 64447 "Not Defined" 64446 "Not Defined" 64445 "Not Defined" 64444 "Not Defined" 64443 "Not Defined" 64442 "Not Defined" 64441 "Not Defined" 64440 "Not Defined" 64439 "Not Defined" 64438 "Not Defined" 64437 "Not Defined" 64436 "Not Defined" 64435 "Not Defined" 64434 "Not Defined" 64433 "Not Defined" 64432 "Not Defined" 64431 "Not Defined" 64430 "Not Defined" 64429 "Not Defined" 64428 "Not Defined" 64427 "Not Defined" 64426 "Not Defined" 64425 "Not Defined" 64424 "Not Defined" 64423 "Not Defined" 64422 "Not Defined" 64421 "Not Defined" 64420 "Not Defined" 64419 "Not Defined" 64418 "Not Defined" 64417 "Not Defined" 64416 "Not Defined" 64415 "Not Defined" 64414 "Not Defined" 64413 "Not Defined" 64412 "Not Defined" 64411 "Not Defined" 64410 "Not Defined" 64409 "Not Defined" 64408 "Not Defined" 64407 "Not Defined" 64406 "Not Defined" 64405 "Not Defined" 64404 "Not Defined" 64403 "Not Defined" 64402 "Not Defined" 64401 "Not Defined" 64400 "Not Defined" 64399 "Not Defined" 64398 "Not Defined" 64397 "Not Defined" 64396 "Not Defined" 64395 "Not Defined" 64394 "Not Defined" 64393 "Not Defined" 64392 "Not Defined" 64391 "Not Defined" 64390 "Not Defined" 64389 "Not Defined" 64388 "Not Defined" 64387 "Not Defined" 64386 "Not Defined" 64385 "Not Defined" 64384 "Not Defined" 64383 "Not Defined" 64382 "Not Defined" 64381 "Not Defined" 64380 "Not Defined" 64379 "Not Defined" 64378 "Not Defined" 64377 "Not Defined" 64376 "Not Defined" 64375 "Not Defined" 64374 "Not Defined" 64373 "Not Defined" 64372 "Not Defined" 64371 "Not Defined" 64370 "Not Defined" 64369 "Not Defined" 64368 "Not Defined" 64367 "Not Defined" 64366 "Not Defined" 64365 "Not Defined" 64364 "Not Defined" 64363 "Not Defined" 64362 "Not Defined" 64361 "Not Defined" 64360 "Not Defined" 64359 "Not Defined" 64358 "Not Defined" 64357 "Not Defined" 64356 "Not Defined" 64355 "Not Defined" 64354 "Not Defined" 64353 "Not Defined" 64352 "Not Defined" 64351 "Not Defined" 64350 "Not Defined" 64349 "Not Defined" 64348 "Not Defined" 64347 "Not Defined" 64346 "Not Defined" 64345 "Not Defined" 64344 "Not Defined" 64343 "Not Defined" 64342 "Not Defined" 64341 "Not Defined" 64340 "Not Defined" 64339 "Not Defined" 64338 "Not Defined" 64337 "Not Defined" 64336 "Not Defined" 64335 "Not Defined" 64334 "Not Defined" 64333 "Not Defined" 64332 "Not Defined" 64331 "Not Defined" 64330 "Not Defined" 64329 "Not Defined" 64328 "Not Defined" 64327 "Not Defined" 64326 "Not Defined" 64325 "Not Defined" 64324 "Not Defined" 64323 "Not Defined" 64322 "Not Defined" 64321 "Not Defined" 64320 "Not Defined" 64319 "Not Defined" 64318 "Not Defined" 64317 "Not Defined" 64316 "Not Defined" 64315 "Not Defined" 64314 "Not Defined" 64313 "Not Defined" 64312 "Not Defined" 64311 "Not Defined" 64310 "Not Defined" 64309 "Not Defined" 64308 "Not Defined" 64307 "Not Defined" 64306 "Not Defined" 64305 "Not Defined" 64304 "Not Defined" 64303 "Not Defined" 64302 "Not Defined" 64301 "Not Defined" 64300 "Not Defined" 64299 "Not Defined" 64298 "Not Defined" 64297 "Not Defined" 64296 "Not Defined" 64295 "Not Defined" 64294 "Not Defined" 64293 "Not Defined" 64292 "Not Defined" 64291 "Not Defined" 64290 "Not Defined" 64289 "Not Defined" 64288 "Not Defined" 64287 "Not Defined" 64286 "Not Defined" 64285 "Not Defined" 64284 "Not Defined" 64283 "Not Defined" 64282 "Not Defined" 64281 "Not Defined" 64280 "Not Defined" 64279 "Not Defined" 64278 "Not Defined" 64277 "Not Defined" 64276 "Not Defined" 64275 "Not Defined" 64274 "Not Defined" 64273 "Not Defined" 64272 "Not Defined" 64271 "Not Defined" 64270 "Not Defined" 64269 "Not Defined" 64268 "Not Defined" 64267 "Not Defined" 64266 "Not Defined" 64265 "Not Defined" 64264 "Not Defined" 64263 "Not Defined" 64262 "Not Defined" 64261 "Not Defined" 64260 "Not Defined" 64259 "Not Defined" 64258 "Not Defined" 64257 "Not Defined" 64256 "Not Defined" ;
VAL_ 2680225593 IAV_AIN5_PressureSensorX 65535 "Signal not available" 64510 "Not Defined" 64509 "Not Defined" 64508 "Not Defined" 64507 "Not Defined" 64506 "Not Defined" 64505 "Not Defined" 64504 "Not Defined" 64503 "Not Defined" 64502 "Not Defined" 64501 "Not Defined" 64500 "Not Defined" 64499 "Not Defined" 64498 "Not Defined" 64497 "Not Defined" 64496 "Not Defined" 64495 "Not Defined" 64494 "Not Defined" 64493 "Not Defined" 64492 "Not Defined" 64491 "Not Defined" 64490 "Not Defined" 64489 "Not Defined" 64488 "Not Defined" 64487 "Not Defined" 64486 "Not Defined" 64485 "Not Defined" 64484 "Not Defined" 64483 "Not Defined" 64482 "Not Defined" 64481 "Not Defined" 64480 "Not Defined" 64479 "Not Defined" 64478 "Not Defined" 64477 "Not Defined" 64476 "Not Defined" 64475 "Not Defined" 64474 "Not Defined" 64473 "Not Defined" 64472 "Not Defined" 64471 "Not Defined" 64470 "Not Defined" 64469 "Not Defined" 64468 "Not Defined" 64467 "Not Defined" 64466 "Not Defined" 64465 "Not Defined" 64464 "Not Defined" 64463 "Not Defined" 64462 "Not Defined" 64461 "Not Defined" 64460 "Not Defined" 64459 "Not Defined" 64458 "Not Defined" 64457 "Not Defined" 64456 "Not Defined" 64455 "Not Defined" 64454 "Not Defined" 64453 "Not Defined" 64452 "Not Defined" 64451 "Not Defined" 64450 "Not Defined" 64449 "Not Defined" 64448 "Not Defined" 64447 "Not Defined" 64446 "Not Defined" 64445 "Not Defined" 64444 "Not Defined" 64443 "Not Defined" 64442 "Not Defined" 64441 "Not Defined" 64440 "Not Defined" 64439 "Not Defined" 64438 "Not Defined" 64437 "Not Defined" 64436 "Not Defined" 64435 "Not Defined" 64434 "Not Defined" 64433 "Not Defined" 64432 "Not Defined" 64431 "Not Defined" 64430 "Not Defined" 64429 "Not Defined" 64428 "Not Defined" 64427 "Not Defined" 64426 "Not Defined" 64425 "Not Defined" 64424 "Not Defined" 64423 "Not Defined" 64422 "Not Defined" 64421 "Not Defined" 64420 "Not Defined" 64419 "Not Defined" 64418 "Not Defined" 64417 "Not Defined" 64416 "Not Defined" 64415 "Not Defined" 64414 "Not Defined" 64413 "Not Defined" 64412 "Not Defined" 64411 "Not Defined" 64410 "Not Defined" 64409 "Not Defined" 64408 "Not Defined" 64407 "Not Defined" 64406 "Not Defined" 64405 "Not Defined" 64404 "Not Defined" 64403 "Not Defined" 64402 "Not Defined" 64401 "Not Defined" 64400 "Not Defined" 64399 "Not Defined" 64398 "Not Defined" 64397 "Not Defined" 64396 "Not Defined" 64395 "Not Defined" 64394 "Not Defined" 64393 "Not Defined" 64392 "Not Defined" 64391 "Not Defined" 64390 "Not Defined" 64389 "Not Defined" 64388 "Not Defined" 64387 "Not Defined" 64386 "Not Defined" 64385 "Not Defined" 64384 "Not Defined" 64383 "Not Defined" 64382 "Not Defined" 64381 "Not Defined" 64380 "Not Defined" 64379 "Not Defined" 64378 "Not Defined" 64377 "Not Defined" 64376 "Not Defined" 64375 "Not Defined" 64374 "Not Defined" 64373 "Not Defined" 64372 "Not Defined" 64371 "Not Defined" 64370 "Not Defined" 64369 "Not Defined" 64368 "Not Defined" 64367 "Not Defined" 64366 "Not Defined" 64365 "Not Defined" 64364 "Not Defined" 64363 "Not Defined" 64362 "Not Defined" 64361 "Not Defined" 64360 "Not Defined" 64359 "Not Defined" 64358 "Not Defined" 64357 "Not Defined" 64356 "Not Defined" 64355 "Not Defined" 64354 "Not Defined" 64353 "Not Defined" 64352 "Not Defined" 64351 "Not Defined" 64350 "Not Defined" 64349 "Not Defined" 64348 "Not Defined" 64347 "Not Defined" 64346 "Not Defined" 64345 "Not Defined" 64344 "Not Defined" 64343 "Not Defined" 64342 "Not Defined" 64341 "Not Defined" 64340 "Not Defined" 64339 "Not Defined" 64338 "Not Defined" 64337 "Not Defined" 64336 "Not Defined" 64335 "Not Defined" 64334 "Not Defined" 64333 "Not Defined" 64332 "Not Defined" 64331 "Not Defined" 64330 "Not Defined" 64329 "Not Defined" 64328 "Not Defined" 64327 "Not Defined" 64326 "Not Defined" 64325 "Not Defined" 64324 "Not Defined" 64323 "Not Defined" 64322 "Not Defined" 64321 "Not Defined" 64320 "Not Defined" 64319 "Not Defined" 64318 "Not Defined" 64317 "Not Defined" 64316 "Not Defined" 64315 "Not Defined" 64314 "Not Defined" 64313 "Not Defined" 64312 "Not Defined" 64311 "Not Defined" 64310 "Not Defined" 64309 "Not Defined" 64308 "Not Defined" 64307 "Not Defined" 64306 "Not Defined" 64305 "Not Defined" 64304 "Not Defined" 64303 "Not Defined" 64302 "Not Defined" 64301 "Not Defined" 64300 "Not Defined" 64299 "Not Defined" 64298 "Not Defined" 64297 "Not Defined" 64296 "Not Defined" 64295 "Not Defined" 64294 "Not Defined" 64293 "Not Defined" 64292 "Not Defined" 64291 "Not Defined" 64290 "Not Defined" 64289 "Not Defined" 64288 "Not Defined" 64287 "Not Defined" 64286 "Not Defined" 64285 "Not Defined" 64284 "Not Defined" 64283 "Not Defined" 64282 "Not Defined" 64281 "Not Defined" 64280 "Not Defined" 64279 "Not Defined" 64278 "Not Defined" 64277 "Not Defined" 64276 "Not Defined" 64275 "Not Defined" 64274 "Not Defined" 64273 "Not Defined" 64272 "Not Defined" 64271 "Not Defined" 64270 "Not Defined" 64269 "Not Defined" 64268 "Not Defined" 64267 "Not Defined" 64266 "Not Defined" 64265 "Not Defined" 64264 "Not Defined" 64263 "Not Defined" 64262 "Not Defined" 64261 "Not Defined" 64260 "Not Defined" 64259 "Not Defined" 64258 "Not Defined" 64257 "Not Defined" 64256 "Not Defined" ;
VAL_ 2680225592 IAV_AIN4_RearAngleRed 65535 "Signal not available" 64510 "Not Defined" 64509 "Not Defined" 64508 "Not Defined" 64507 "Not Defined" 64506 "Not Defined" 64505 "Not Defined" 64504 "Not Defined" 64503 "Not Defined" 64502 "Not Defined" 64501 "Not Defined" 64500 "Not Defined" 64499 "Not Defined" 64498 "Not Defined" 64497 "Not Defined" 64496 "Not Defined" 64495 "Not Defined" 64494 "Not Defined" 64493 "Not Defined" 64492 "Not Defined" 64491 "Not Defined" 64490 "Not Defined" 64489 "Not Defined" 64488 "Not Defined" 64487 "Not Defined" 64486 "Not Defined" 64485 "Not Defined" 64484 "Not Defined" 64483 "Not Defined" 64482 "Not Defined" 64481 "Not Defined" 64480 "Not Defined" 64479 "Not Defined" 64478 "Not Defined" 64477 "Not Defined" 64476 "Not Defined" 64475 "Not Defined" 64474 "Not Defined" 64473 "Not Defined" 64472 "Not Defined" 64471 "Not Defined" 64470 "Not Defined" 64469 "Not Defined" 64468 "Not Defined" 64467 "Not Defined" 64466 "Not Defined" 64465 "Not Defined" 64464 "Not Defined" 64463 "Not Defined" 64462 "Not Defined" 64461 "Not Defined" 64460 "Not Defined" 64459 "Not Defined" 64458 "Not Defined" 64457 "Not Defined" 64456 "Not Defined" 64455 "Not Defined" 64454 "Not Defined" 64453 "Not Defined" 64452 "Not Defined" 64451 "Not Defined" 64450 "Not Defined" 64449 "Not Defined" 64448 "Not Defined" 64447 "Not Defined" 64446 "Not Defined" 64445 "Not Defined" 64444 "Not Defined" 64443 "Not Defined" 64442 "Not Defined" 64441 "Not Defined" 64440 "Not Defined" 64439 "Not Defined" 64438 "Not Defined" 64437 "Not Defined" 64436 "Not Defined" 64435 "Not Defined" 64434 "Not Defined" 64433 "Not Defined" 64432 "Not Defined" 64431 "Not Defined" 64430 "Not Defined" 64429 "Not Defined" 64428 "Not Defined" 64427 "Not Defined" 64426 "Not Defined" 64425 "Not Defined" 64424 "Not Defined" 64423 "Not Defined" 64422 "Not Defined" 64421 "Not Defined" 64420 "Not Defined" 64419 "Not Defined" 64418 "Not Defined" 64417 "Not Defined" 64416 "Not Defined" 64415 "Not Defined" 64414 "Not Defined" 64413 "Not Defined" 64412 "Not Defined" 64411 "Not Defined" 64410 "Not Defined" 64409 "Not Defined" 64408 "Not Defined" 64407 "Not Defined" 64406 "Not Defined" 64405 "Not Defined" 64404 "Not Defined" 64403 "Not Defined" 64402 "Not Defined" 64401 "Not Defined" 64400 "Not Defined" 64399 "Not Defined" 64398 "Not Defined" 64397 "Not Defined" 64396 "Not Defined" 64395 "Not Defined" 64394 "Not Defined" 64393 "Not Defined" 64392 "Not Defined" 64391 "Not Defined" 64390 "Not Defined" 64389 "Not Defined" 64388 "Not Defined" 64387 "Not Defined" 64386 "Not Defined" 64385 "Not Defined" 64384 "Not Defined" 64383 "Not Defined" 64382 "Not Defined" 64381 "Not Defined" 64380 "Not Defined" 64379 "Not Defined" 64378 "Not Defined" 64377 "Not Defined" 64376 "Not Defined" 64375 "Not Defined" 64374 "Not Defined" 64373 "Not Defined" 64372 "Not Defined" 64371 "Not Defined" 64370 "Not Defined" 64369 "Not Defined" 64368 "Not Defined" 64367 "Not Defined" 64366 "Not Defined" 64365 "Not Defined" 64364 "Not Defined" 64363 "Not Defined" 64362 "Not Defined" 64361 "Not Defined" 64360 "Not Defined" 64359 "Not Defined" 64358 "Not Defined" 64357 "Not Defined" 64356 "Not Defined" 64355 "Not Defined" 64354 "Not Defined" 64353 "Not Defined" 64352 "Not Defined" 64351 "Not Defined" 64350 "Not Defined" 64349 "Not Defined" 64348 "Not Defined" 64347 "Not Defined" 64346 "Not Defined" 64345 "Not Defined" 64344 "Not Defined" 64343 "Not Defined" 64342 "Not Defined" 64341 "Not Defined" 64340 "Not Defined" 64339 "Not Defined" 64338 "Not Defined" 64337 "Not Defined" 64336 "Not Defined" 64335 "Not Defined" 64334 "Not Defined" 64333 "Not Defined" 64332 "Not Defined" 64331 "Not Defined" 64330 "Not Defined" 64329 "Not Defined" 64328 "Not Defined" 64327 "Not Defined" 64326 "Not Defined" 64325 "Not Defined" 64324 "Not Defined" 64323 "Not Defined" 64322 "Not Defined" 64321 "Not Defined" 64320 "Not Defined" 64319 "Not Defined" 64318 "Not Defined" 64317 "Not Defined" 64316 "Not Defined" 64315 "Not Defined" 64314 "Not Defined" 64313 "Not Defined" 64312 "Not Defined" 64311 "Not Defined" 64310 "Not Defined" 64309 "Not Defined" 64308 "Not Defined" 64307 "Not Defined" 64306 "Not Defined" 64305 "Not Defined" 64304 "Not Defined" 64303 "Not Defined" 64302 "Not Defined" 64301 "Not Defined" 64300 "Not Defined" 64299 "Not Defined" 64298 "Not Defined" 64297 "Not Defined" 64296 "Not Defined" 64295 "Not Defined" 64294 "Not Defined" 64293 "Not Defined" 64292 "Not Defined" 64291 "Not Defined" 64290 "Not Defined" 64289 "Not Defined" 64288 "Not Defined" 64287 "Not Defined" 64286 "Not Defined" 64285 "Not Defined" 64284 "Not Defined" 64283 "Not Defined" 64282 "Not Defined" 64281 "Not Defined" 64280 "Not Defined" 64279 "Not Defined" 64278 "Not Defined" 64277 "Not Defined" 64276 "Not Defined" 64275 "Not Defined" 64274 "Not Defined" 64273 "Not Defined" 64272 "Not Defined" 64271 "Not Defined" 64270 "Not Defined" 64269 "Not Defined" 64268 "Not Defined" 64267 "Not Defined" 64266 "Not Defined" 64265 "Not Defined" 64264 "Not Defined" 64263 "Not Defined" 64262 "Not Defined" 64261 "Not Defined" 64260 "Not Defined" 64259 "Not Defined" 64258 "Not Defined" 64257 "Not Defined" 64256 "Not Defined" ;
VAL_ 2680225592 IAV_AIN3_RearAngle 65535 "Signal not available" 64510 "Not Defined" 64509 "Not Defined" 64508 "Not Defined" 64507 "Not Defined" 64506 "Not Defined" 64505 "Not Defined" 64504 "Not Defined" 64503 "Not Defined" 64502 "Not Defined" 64501 "Not Defined" 64500 "Not Defined" 64499 "Not Defined" 64498 "Not Defined" 64497 "Not Defined" 64496 "Not Defined" 64495 "Not Defined" 64494 "Not Defined" 64493 "Not Defined" 64492 "Not Defined" 64491 "Not Defined" 64490 "Not Defined" 64489 "Not Defined" 64488 "Not Defined" 64487 "Not Defined" 64486 "Not Defined" 64485 "Not Defined" 64484 "Not Defined" 64483 "Not Defined" 64482 "Not Defined" 64481 "Not Defined" 64480 "Not Defined" 64479 "Not Defined" 64478 "Not Defined" 64477 "Not Defined" 64476 "Not Defined" 64475 "Not Defined" 64474 "Not Defined" 64473 "Not Defined" 64472 "Not Defined" 64471 "Not Defined" 64470 "Not Defined" 64469 "Not Defined" 64468 "Not Defined" 64467 "Not Defined" 64466 "Not Defined" 64465 "Not Defined" 64464 "Not Defined" 64463 "Not Defined" 64462 "Not Defined" 64461 "Not Defined" 64460 "Not Defined" 64459 "Not Defined" 64458 "Not Defined" 64457 "Not Defined" 64456 "Not Defined" 64455 "Not Defined" 64454 "Not Defined" 64453 "Not Defined" 64452 "Not Defined" 64451 "Not Defined" 64450 "Not Defined" 64449 "Not Defined" 64448 "Not Defined" 64447 "Not Defined" 64446 "Not Defined" 64445 "Not Defined" 64444 "Not Defined" 64443 "Not Defined" 64442 "Not Defined" 64441 "Not Defined" 64440 "Not Defined" 64439 "Not Defined" 64438 "Not Defined" 64437 "Not Defined" 64436 "Not Defined" 64435 "Not Defined" 64434 "Not Defined" 64433 "Not Defined" 64432 "Not Defined" 64431 "Not Defined" 64430 "Not Defined" 64429 "Not Defined" 64428 "Not Defined" 64427 "Not Defined" 64426 "Not Defined" 64425 "Not Defined" 64424 "Not Defined" 64423 "Not Defined" 64422 "Not Defined" 64421 "Not Defined" 64420 "Not Defined" 64419 "Not Defined" 64418 "Not Defined" 64417 "Not Defined" 64416 "Not Defined" 64415 "Not Defined" 64414 "Not Defined" 64413 "Not Defined" 64412 "Not Defined" 64411 "Not Defined" 64410 "Not Defined" 64409 "Not Defined" 64408 "Not Defined" 64407 "Not Defined" 64406 "Not Defined" 64405 "Not Defined" 64404 "Not Defined" 64403 "Not Defined" 64402 "Not Defined" 64401 "Not Defined" 64400 "Not Defined" 64399 "Not Defined" 64398 "Not Defined" 64397 "Not Defined" 64396 "Not Defined" 64395 "Not Defined" 64394 "Not Defined" 64393 "Not Defined" 64392 "Not Defined" 64391 "Not Defined" 64390 "Not Defined" 64389 "Not Defined" 64388 "Not Defined" 64387 "Not Defined" 64386 "Not Defined" 64385 "Not Defined" 64384 "Not Defined" 64383 "Not Defined" 64382 "Not Defined" 64381 "Not Defined" 64380 "Not Defined" 64379 "Not Defined" 64378 "Not Defined" 64377 "Not Defined" 64376 "Not Defined" 64375 "Not Defined" 64374 "Not Defined" 64373 "Not Defined" 64372 "Not Defined" 64371 "Not Defined" 64370 "Not Defined" 64369 "Not Defined" 64368 "Not Defined" 64367 "Not Defined" 64366 "Not Defined" 64365 "Not Defined" 64364 "Not Defined" 64363 "Not Defined" 64362 "Not Defined" 64361 "Not Defined" 64360 "Not Defined" 64359 "Not Defined" 64358 "Not Defined" 64357 "Not Defined" 64356 "Not Defined" 64355 "Not Defined" 64354 "Not Defined" 64353 "Not Defined" 64352 "Not Defined" 64351 "Not Defined" 64350 "Not Defined" 64349 "Not Defined" 64348 "Not Defined" 64347 "Not Defined" 64346 "Not Defined" 64345 "Not Defined" 64344 "Not Defined" 64343 "Not Defined" 64342 "Not Defined" 64341 "Not Defined" 64340 "Not Defined" 64339 "Not Defined" 64338 "Not Defined" 64337 "Not Defined" 64336 "Not Defined" 64335 "Not Defined" 64334 "Not Defined" 64333 "Not Defined" 64332 "Not Defined" 64331 "Not Defined" 64330 "Not Defined" 64329 "Not Defined" 64328 "Not Defined" 64327 "Not Defined" 64326 "Not Defined" 64325 "Not Defined" 64324 "Not Defined" 64323 "Not Defined" 64322 "Not Defined" 64321 "Not Defined" 64320 "Not Defined" 64319 "Not Defined" 64318 "Not Defined" 64317 "Not Defined" 64316 "Not Defined" 64315 "Not Defined" 64314 "Not Defined" 64313 "Not Defined" 64312 "Not Defined" 64311 "Not Defined" 64310 "Not Defined" 64309 "Not Defined" 64308 "Not Defined" 64307 "Not Defined" 64306 "Not Defined" 64305 "Not Defined" 64304 "Not Defined" 64303 "Not Defined" 64302 "Not Defined" 64301 "Not Defined" 64300 "Not Defined" 64299 "Not Defined" 64298 "Not Defined" 64297 "Not Defined" 64296 "Not Defined" 64295 "Not Defined" 64294 "Not Defined" 64293 "Not Defined" 64292 "Not Defined" 64291 "Not Defined" 64290 "Not Defined" 64289 "Not Defined" 64288 "Not Defined" 64287 "Not Defined" 64286 "Not Defined" 64285 "Not Defined" 64284 "Not Defined" 64283 "Not Defined" 64282 "Not Defined" 64281 "Not Defined" 64280 "Not Defined" 64279 "Not Defined" 64278 "Not Defined" 64277 "Not Defined" 64276 "Not Defined" 64275 "Not Defined" 64274 "Not Defined" 64273 "Not Defined" 64272 "Not Defined" 64271 "Not Defined" 64270 "Not Defined" 64269 "Not Defined" 64268 "Not Defined" 64267 "Not Defined" 64266 "Not Defined" 64265 "Not Defined" 64264 "Not Defined" 64263 "Not Defined" 64262 "Not Defined" 64261 "Not Defined" 64260 "Not Defined" 64259 "Not Defined" 64258 "Not Defined" 64257 "Not Defined" 64256 "Not Defined" ;
VAL_ 2680225592 IAV_AIN2_FrontAngleRed 65535 "Signal not available" 64510 "Not Defined" 64509 "Not Defined" 64508 "Not Defined" 64507 "Not Defined" 64506 "Not Defined" 64505 "Not Defined" 64504 "Not Defined" 64503 "Not Defined" 64502 "Not Defined" 64501 "Not Defined" 64500 "Not Defined" 64499 "Not Defined" 64498 "Not Defined" 64497 "Not Defined" 64496 "Not Defined" 64495 "Not Defined" 64494 "Not Defined" 64493 "Not Defined" 64492 "Not Defined" 64491 "Not Defined" 64490 "Not Defined" 64489 "Not Defined" 64488 "Not Defined" 64487 "Not Defined" 64486 "Not Defined" 64485 "Not Defined" 64484 "Not Defined" 64483 "Not Defined" 64482 "Not Defined" 64481 "Not Defined" 64480 "Not Defined" 64479 "Not Defined" 64478 "Not Defined" 64477 "Not Defined" 64476 "Not Defined" 64475 "Not Defined" 64474 "Not Defined" 64473 "Not Defined" 64472 "Not Defined" 64471 "Not Defined" 64470 "Not Defined" 64469 "Not Defined" 64468 "Not Defined" 64467 "Not Defined" 64466 "Not Defined" 64465 "Not Defined" 64464 "Not Defined" 64463 "Not Defined" 64462 "Not Defined" 64461 "Not Defined" 64460 "Not Defined" 64459 "Not Defined" 64458 "Not Defined" 64457 "Not Defined" 64456 "Not Defined" 64455 "Not Defined" 64454 "Not Defined" 64453 "Not Defined" 64452 "Not Defined" 64451 "Not Defined" 64450 "Not Defined" 64449 "Not Defined" 64448 "Not Defined" 64447 "Not Defined" 64446 "Not Defined" 64445 "Not Defined" 64444 "Not Defined" 64443 "Not Defined" 64442 "Not Defined" 64441 "Not Defined" 64440 "Not Defined" 64439 "Not Defined" 64438 "Not Defined" 64437 "Not Defined" 64436 "Not Defined" 64435 "Not Defined" 64434 "Not Defined" 64433 "Not Defined" 64432 "Not Defined" 64431 "Not Defined" 64430 "Not Defined" 64429 "Not Defined" 64428 "Not Defined" 64427 "Not Defined" 64426 "Not Defined" 64425 "Not Defined" 64424 "Not Defined" 64423 "Not Defined" 64422 "Not Defined" 64421 "Not Defined" 64420 "Not Defined" 64419 "Not Defined" 64418 "Not Defined" 64417 "Not Defined" 64416 "Not Defined" 64415 "Not Defined" 64414 "Not Defined" 64413 "Not Defined" 64412 "Not Defined" 64411 "Not Defined" 64410 "Not Defined" 64409 "Not Defined" 64408 "Not Defined" 64407 "Not Defined" 64406 "Not Defined" 64405 "Not Defined" 64404 "Not Defined" 64403 "Not Defined" 64402 "Not Defined" 64401 "Not Defined" 64400 "Not Defined" 64399 "Not Defined" 64398 "Not Defined" 64397 "Not Defined" 64396 "Not Defined" 64395 "Not Defined" 64394 "Not Defined" 64393 "Not Defined" 64392 "Not Defined" 64391 "Not Defined" 64390 "Not Defined" 64389 "Not Defined" 64388 "Not Defined" 64387 "Not Defined" 64386 "Not Defined" 64385 "Not Defined" 64384 "Not Defined" 64383 "Not Defined" 64382 "Not Defined" 64381 "Not Defined" 64380 "Not Defined" 64379 "Not Defined" 64378 "Not Defined" 64377 "Not Defined" 64376 "Not Defined" 64375 "Not Defined" 64374 "Not Defined" 64373 "Not Defined" 64372 "Not Defined" 64371 "Not Defined" 64370 "Not Defined" 64369 "Not Defined" 64368 "Not Defined" 64367 "Not Defined" 64366 "Not Defined" 64365 "Not Defined" 64364 "Not Defined" 64363 "Not Defined" 64362 "Not Defined" 64361 "Not Defined" 64360 "Not Defined" 64359 "Not Defined" 64358 "Not Defined" 64357 "Not Defined" 64356 "Not Defined" 64355 "Not Defined" 64354 "Not Defined" 64353 "Not Defined" 64352 "Not Defined" 64351 "Not Defined" 64350 "Not Defined" 64349 "Not Defined" 64348 "Not Defined" 64347 "Not Defined" 64346 "Not Defined" 64345 "Not Defined" 64344 "Not Defined" 64343 "Not Defined" 64342 "Not Defined" 64341 "Not Defined" 64340 "Not Defined" 64339 "Not Defined" 64338 "Not Defined" 64337 "Not Defined" 64336 "Not Defined" 64335 "Not Defined" 64334 "Not Defined" 64333 "Not Defined" 64332 "Not Defined" 64331 "Not Defined" 64330 "Not Defined" 64329 "Not Defined" 64328 "Not Defined" 64327 "Not Defined" 64326 "Not Defined" 64325 "Not Defined" 64324 "Not Defined" 64323 "Not Defined" 64322 "Not Defined" 64321 "Not Defined" 64320 "Not Defined" 64319 "Not Defined" 64318 "Not Defined" 64317 "Not Defined" 64316 "Not Defined" 64315 "Not Defined" 64314 "Not Defined" 64313 "Not Defined" 64312 "Not Defined" 64311 "Not Defined" 64310 "Not Defined" 64309 "Not Defined" 64308 "Not Defined" 64307 "Not Defined" 64306 "Not Defined" 64305 "Not Defined" 64304 "Not Defined" 64303 "Not Defined" 64302 "Not Defined" 64301 "Not Defined" 64300 "Not Defined" 64299 "Not Defined" 64298 "Not Defined" 64297 "Not Defined" 64296 "Not Defined" 64295 "Not Defined" 64294 "Not Defined" 64293 "Not Defined" 64292 "Not Defined" 64291 "Not Defined" 64290 "Not Defined" 64289 "Not Defined" 64288 "Not Defined" 64287 "Not Defined" 64286 "Not Defined" 64285 "Not Defined" 64284 "Not Defined" 64283 "Not Defined" 64282 "Not Defined" 64281 "Not Defined" 64280 "Not Defined" 64279 "Not Defined" 64278 "Not Defined" 64277 "Not Defined" 64276 "Not Defined" 64275 "Not Defined" 64274 "Not Defined" 64273 "Not Defined" 64272 "Not Defined" 64271 "Not Defined" 64270 "Not Defined" 64269 "Not Defined" 64268 "Not Defined" 64267 "Not Defined" 64266 "Not Defined" 64265 "Not Defined" 64264 "Not Defined" 64263 "Not Defined" 64262 "Not Defined" 64261 "Not Defined" 64260 "Not Defined" 64259 "Not Defined" 64258 "Not Defined" 64257 "Not Defined" 64256 "Not Defined" ;
VAL_ 2680225592 IAV_AIN1_FrontAngle 65535 "Signal not available" 64510 "Not Defined" 64509 "Not Defined" 64508 "Not Defined" 64507 "Not Defined" 64506 "Not Defined" 64505 "Not Defined" 64504 "Not Defined" 64503 "Not Defined" 64502 "Not Defined" 64501 "Not Defined" 64500 "Not Defined" 64499 "Not Defined" 64498 "Not Defined" 64497 "Not Defined" 64496 "Not Defined" 64495 "Not Defined" 64494 "Not Defined" 64493 "Not Defined" 64492 "Not Defined" 64491 "Not Defined" 64490 "Not Defined" 64489 "Not Defined" 64488 "Not Defined" 64487 "Not Defined" 64486 "Not Defined" 64485 "Not Defined" 64484 "Not Defined" 64483 "Not Defined" 64482 "Not Defined" 64481 "Not Defined" 64480 "Not Defined" 64479 "Not Defined" 64478 "Not Defined" 64477 "Not Defined" 64476 "Not Defined" 64475 "Not Defined" 64474 "Not Defined" 64473 "Not Defined" 64472 "Not Defined" 64471 "Not Defined" 64470 "Not Defined" 64469 "Not Defined" 64468 "Not Defined" 64467 "Not Defined" 64466 "Not Defined" 64465 "Not Defined" 64464 "Not Defined" 64463 "Not Defined" 64462 "Not Defined" 64461 "Not Defined" 64460 "Not Defined" 64459 "Not Defined" 64458 "Not Defined" 64457 "Not Defined" 64456 "Not Defined" 64455 "Not Defined" 64454 "Not Defined" 64453 "Not Defined" 64452 "Not Defined" 64451 "Not Defined" 64450 "Not Defined" 64449 "Not Defined" 64448 "Not Defined" 64447 "Not Defined" 64446 "Not Defined" 64445 "Not Defined" 64444 "Not Defined" 64443 "Not Defined" 64442 "Not Defined" 64441 "Not Defined" 64440 "Not Defined" 64439 "Not Defined" 64438 "Not Defined" 64437 "Not Defined" 64436 "Not Defined" 64435 "Not Defined" 64434 "Not Defined" 64433 "Not Defined" 64432 "Not Defined" 64431 "Not Defined" 64430 "Not Defined" 64429 "Not Defined" 64428 "Not Defined" 64427 "Not Defined" 64426 "Not Defined" 64425 "Not Defined" 64424 "Not Defined" 64423 "Not Defined" 64422 "Not Defined" 64421 "Not Defined" 64420 "Not Defined" 64419 "Not Defined" 64418 "Not Defined" 64417 "Not Defined" 64416 "Not Defined" 64415 "Not Defined" 64414 "Not Defined" 64413 "Not Defined" 64412 "Not Defined" 64411 "Not Defined" 64410 "Not Defined" 64409 "Not Defined" 64408 "Not Defined" 64407 "Not Defined" 64406 "Not Defined" 64405 "Not Defined" 64404 "Not Defined" 64403 "Not Defined" 64402 "Not Defined" 64401 "Not Defined" 64400 "Not Defined" 64399 "Not Defined" 64398 "Not Defined" 64397 "Not Defined" 64396 "Not Defined" 64395 "Not Defined" 64394 "Not Defined" 64393 "Not Defined" 64392 "Not Defined" 64391 "Not Defined" 64390 "Not Defined" 64389 "Not Defined" 64388 "Not Defined" 64387 "Not Defined" 64386 "Not Defined" 64385 "Not Defined" 64384 "Not Defined" 64383 "Not Defined" 64382 "Not Defined" 64381 "Not Defined" 64380 "Not Defined" 64379 "Not Defined" 64378 "Not Defined" 64377 "Not Defined" 64376 "Not Defined" 64375 "Not Defined" 64374 "Not Defined" 64373 "Not Defined" 64372 "Not Defined" 64371 "Not Defined" 64370 "Not Defined" 64369 "Not Defined" 64368 "Not Defined" 64367 "Not Defined" 64366 "Not Defined" 64365 "Not Defined" 64364 "Not Defined" 64363 "Not Defined" 64362 "Not Defined" 64361 "Not Defined" 64360 "Not Defined" 64359 "Not Defined" 64358 "Not Defined" 64357 "Not Defined" 64356 "Not Defined" 64355 "Not Defined" 64354 "Not Defined" 64353 "Not Defined" 64352 "Not Defined" 64351 "Not Defined" 64350 "Not Defined" 64349 "Not Defined" 64348 "Not Defined" 64347 "Not Defined" 64346 "Not Defined" 64345 "Not Defined" 64344 "Not Defined" 64343 "Not Defined" 64342 "Not Defined" 64341 "Not Defined" 64340 "Not Defined" 64339 "Not Defined" 64338 "Not Defined" 64337 "Not Defined" 64336 "Not Defined" 64335 "Not Defined" 64334 "Not Defined" 64333 "Not Defined" 64332 "Not Defined" 64331 "Not Defined" 64330 "Not Defined" 64329 "Not Defined" 64328 "Not Defined" 64327 "Not Defined" 64326 "Not Defined" 64325 "Not Defined" 64324 "Not Defined" 64323 "Not Defined" 64322 "Not Defined" 64321 "Not Defined" 64320 "Not Defined" 64319 "Not Defined" 64318 "Not Defined" 64317 "Not Defined" 64316 "Not Defined" 64315 "Not Defined" 64314 "Not Defined" 64313 "Not Defined" 64312 "Not Defined" 64311 "Not Defined" 64310 "Not Defined" 64309 "Not Defined" 64308 "Not Defined" 64307 "Not Defined" 64306 "Not Defined" 64305 "Not Defined" 64304 "Not Defined" 64303 "Not Defined" 64302 "Not Defined" 64301 "Not Defined" 64300 "Not Defined" 64299 "Not Defined" 64298 "Not Defined" 64297 "Not Defined" 64296 "Not Defined" 64295 "Not Defined" 64294 "Not Defined" 64293 "Not Defined" 64292 "Not Defined" 64291 "Not Defined" 64290 "Not Defined" 64289 "Not Defined" 64288 "Not Defined" 64287 "Not Defined" 64286 "Not Defined" 64285 "Not Defined" 64284 "Not Defined" 64283 "Not Defined" 64282 "Not Defined" 64281 "Not Defined" 64280 "Not Defined" 64279 "Not Defined" 64278 "Not Defined" 64277 "Not Defined" 64276 "Not Defined" 64275 "Not Defined" 64274 "Not Defined" 64273 "Not Defined" 64272 "Not Defined" 64271 "Not Defined" 64270 "Not Defined" 64269 "Not Defined" 64268 "Not Defined" 64267 "Not Defined" 64266 "Not Defined" 64265 "Not Defined" 64264 "Not Defined" 64263 "Not Defined" 64262 "Not Defined" 64261 "Not Defined" 64260 "Not Defined" 64259 "Not Defined" 64258 "Not Defined" 64257 "Not Defined" 64256 "Not Defined" ;
VAL_ 2680225585 PSV_SupV8_PressureSensor 65535 "Signal not available" 64510 "Not Defined" 64509 "Not Defined" 64508 "Not Defined" 64507 "Not Defined" 64506 "Not Defined" 64505 "Not Defined" 64504 "Not Defined" 64503 "Not Defined" 64502 "Not Defined" 64501 "Not Defined" 64500 "Not Defined" 64499 "Not Defined" 64498 "Not Defined" 64497 "Not Defined" 64496 "Not Defined" 64495 "Not Defined" 64494 "Not Defined" 64493 "Not Defined" 64492 "Not Defined" 64491 "Not Defined" 64490 "Not Defined" 64489 "Not Defined" 64488 "Not Defined" 64487 "Not Defined" 64486 "Not Defined" 64485 "Not Defined" 64484 "Not Defined" 64483 "Not Defined" 64482 "Not Defined" 64481 "Not Defined" 64480 "Not Defined" 64479 "Not Defined" 64478 "Not Defined" 64477 "Not Defined" 64476 "Not Defined" 64475 "Not Defined" 64474 "Not Defined" 64473 "Not Defined" 64472 "Not Defined" 64471 "Not Defined" 64470 "Not Defined" 64469 "Not Defined" 64468 "Not Defined" 64467 "Not Defined" 64466 "Not Defined" 64465 "Not Defined" 64464 "Not Defined" 64463 "Not Defined" 64462 "Not Defined" 64461 "Not Defined" 64460 "Not Defined" 64459 "Not Defined" 64458 "Not Defined" 64457 "Not Defined" 64456 "Not Defined" 64455 "Not Defined" 64454 "Not Defined" 64453 "Not Defined" 64452 "Not Defined" 64451 "Not Defined" 64450 "Not Defined" 64449 "Not Defined" 64448 "Not Defined" 64447 "Not Defined" 64446 "Not Defined" 64445 "Not Defined" 64444 "Not Defined" 64443 "Not Defined" 64442 "Not Defined" 64441 "Not Defined" 64440 "Not Defined" 64439 "Not Defined" 64438 "Not Defined" 64437 "Not Defined" 64436 "Not Defined" 64435 "Not Defined" 64434 "Not Defined" 64433 "Not Defined" 64432 "Not Defined" 64431 "Not Defined" 64430 "Not Defined" 64429 "Not Defined" 64428 "Not Defined" 64427 "Not Defined" 64426 "Not Defined" 64425 "Not Defined" 64424 "Not Defined" 64423 "Not Defined" 64422 "Not Defined" 64421 "Not Defined" 64420 "Not Defined" 64419 "Not Defined" 64418 "Not Defined" 64417 "Not Defined" 64416 "Not Defined" 64415 "Not Defined" 64414 "Not Defined" 64413 "Not Defined" 64412 "Not Defined" 64411 "Not Defined" 64410 "Not Defined" 64409 "Not Defined" 64408 "Not Defined" 64407 "Not Defined" 64406 "Not Defined" 64405 "Not Defined" 64404 "Not Defined" 64403 "Not Defined" 64402 "Not Defined" 64401 "Not Defined" 64400 "Not Defined" 64399 "Not Defined" 64398 "Not Defined" 64397 "Not Defined" 64396 "Not Defined" 64395 "Not Defined" 64394 "Not Defined" 64393 "Not Defined" 64392 "Not Defined" 64391 "Not Defined" 64390 "Not Defined" 64389 "Not Defined" 64388 "Not Defined" 64387 "Not Defined" 64386 "Not Defined" 64385 "Not Defined" 64384 "Not Defined" 64383 "Not Defined" 64382 "Not Defined" 64381 "Not Defined" 64380 "Not Defined" 64379 "Not Defined" 64378 "Not Defined" 64377 "Not Defined" 64376 "Not Defined" 64375 "Not Defined" 64374 "Not Defined" 64373 "Not Defined" 64372 "Not Defined" 64371 "Not Defined" 64370 "Not Defined" 64369 "Not Defined" 64368 "Not Defined" 64367 "Not Defined" 64366 "Not Defined" 64365 "Not Defined" 64364 "Not Defined" 64363 "Not Defined" 64362 "Not Defined" 64361 "Not Defined" 64360 "Not Defined" 64359 "Not Defined" 64358 "Not Defined" 64357 "Not Defined" 64356 "Not Defined" 64355 "Not Defined" 64354 "Not Defined" 64353 "Not Defined" 64352 "Not Defined" 64351 "Not Defined" 64350 "Not Defined" 64349 "Not Defined" 64348 "Not Defined" 64347 "Not Defined" 64346 "Not Defined" 64345 "Not Defined" 64344 "Not Defined" 64343 "Not Defined" 64342 "Not Defined" 64341 "Not Defined" 64340 "Not Defined" 64339 "Not Defined" 64338 "Not Defined" 64337 "Not Defined" 64336 "Not Defined" 64335 "Not Defined" 64334 "Not Defined" 64333 "Not Defined" 64332 "Not Defined" 64331 "Not Defined" 64330 "Not Defined" 64329 "Not Defined" 64328 "Not Defined" 64327 "Not Defined" 64326 "Not Defined" 64325 "Not Defined" 64324 "Not Defined" 64323 "Not Defined" 64322 "Not Defined" 64321 "Not Defined" 64320 "Not Defined" 64319 "Not Defined" 64318 "Not Defined" 64317 "Not Defined" 64316 "Not Defined" 64315 "Not Defined" 64314 "Not Defined" 64313 "Not Defined" 64312 "Not Defined" 64311 "Not Defined" 64310 "Not Defined" 64309 "Not Defined" 64308 "Not Defined" 64307 "Not Defined" 64306 "Not Defined" 64305 "Not Defined" 64304 "Not Defined" 64303 "Not Defined" 64302 "Not Defined" 64301 "Not Defined" 64300 "Not Defined" 64299 "Not Defined" 64298 "Not Defined" 64297 "Not Defined" 64296 "Not Defined" 64295 "Not Defined" 64294 "Not Defined" 64293 "Not Defined" 64292 "Not Defined" 64291 "Not Defined" 64290 "Not Defined" 64289 "Not Defined" 64288 "Not Defined" 64287 "Not Defined" 64286 "Not Defined" 64285 "Not Defined" 64284 "Not Defined" 64283 "Not Defined" 64282 "Not Defined" 64281 "Not Defined" 64280 "Not Defined" 64279 "Not Defined" 64278 "Not Defined" 64277 "Not Defined" 64276 "Not Defined" 64275 "Not Defined" 64274 "Not Defined" 64273 "Not Defined" 64272 "Not Defined" 64271 "Not Defined" 64270 "Not Defined" 64269 "Not Defined" 64268 "Not Defined" 64267 "Not Defined" 64266 "Not Defined" 64265 "Not Defined" 64264 "Not Defined" 64263 "Not Defined" 64262 "Not Defined" 64261 "Not Defined" 64260 "Not Defined" 64259 "Not Defined" 64258 "Not Defined" 64257 "Not Defined" 64256 "Not Defined" ;
VAL_ 2680225585 PSV_SupV7_AngleSensor 65535 "Signal not available" 64510 "Not Defined" 64509 "Not Defined" 64508 "Not Defined" 64507 "Not Defined" 64506 "Not Defined" 64505 "Not Defined" 64504 "Not Defined" 64503 "Not Defined" 64502 "Not Defined" 64501 "Not Defined" 64500 "Not Defined" 64499 "Not Defined" 64498 "Not Defined" 64497 "Not Defined" 64496 "Not Defined" 64495 "Not Defined" 64494 "Not Defined" 64493 "Not Defined" 64492 "Not Defined" 64491 "Not Defined" 64490 "Not Defined" 64489 "Not Defined" 64488 "Not Defined" 64487 "Not Defined" 64486 "Not Defined" 64485 "Not Defined" 64484 "Not Defined" 64483 "Not Defined" 64482 "Not Defined" 64481 "Not Defined" 64480 "Not Defined" 64479 "Not Defined" 64478 "Not Defined" 64477 "Not Defined" 64476 "Not Defined" 64475 "Not Defined" 64474 "Not Defined" 64473 "Not Defined" 64472 "Not Defined" 64471 "Not Defined" 64470 "Not Defined" 64469 "Not Defined" 64468 "Not Defined" 64467 "Not Defined" 64466 "Not Defined" 64465 "Not Defined" 64464 "Not Defined" 64463 "Not Defined" 64462 "Not Defined" 64461 "Not Defined" 64460 "Not Defined" 64459 "Not Defined" 64458 "Not Defined" 64457 "Not Defined" 64456 "Not Defined" 64455 "Not Defined" 64454 "Not Defined" 64453 "Not Defined" 64452 "Not Defined" 64451 "Not Defined" 64450 "Not Defined" 64449 "Not Defined" 64448 "Not Defined" 64447 "Not Defined" 64446 "Not Defined" 64445 "Not Defined" 64444 "Not Defined" 64443 "Not Defined" 64442 "Not Defined" 64441 "Not Defined" 64440 "Not Defined" 64439 "Not Defined" 64438 "Not Defined" 64437 "Not Defined" 64436 "Not Defined" 64435 "Not Defined" 64434 "Not Defined" 64433 "Not Defined" 64432 "Not Defined" 64431 "Not Defined" 64430 "Not Defined" 64429 "Not Defined" 64428 "Not Defined" 64427 "Not Defined" 64426 "Not Defined" 64425 "Not Defined" 64424 "Not Defined" 64423 "Not Defined" 64422 "Not Defined" 64421 "Not Defined" 64420 "Not Defined" 64419 "Not Defined" 64418 "Not Defined" 64417 "Not Defined" 64416 "Not Defined" 64415 "Not Defined" 64414 "Not Defined" 64413 "Not Defined" 64412 "Not Defined" 64411 "Not Defined" 64410 "Not Defined" 64409 "Not Defined" 64408 "Not Defined" 64407 "Not Defined" 64406 "Not Defined" 64405 "Not Defined" 64404 "Not Defined" 64403 "Not Defined" 64402 "Not Defined" 64401 "Not Defined" 64400 "Not Defined" 64399 "Not Defined" 64398 "Not Defined" 64397 "Not Defined" 64396 "Not Defined" 64395 "Not Defined" 64394 "Not Defined" 64393 "Not Defined" 64392 "Not Defined" 64391 "Not Defined" 64390 "Not Defined" 64389 "Not Defined" 64388 "Not Defined" 64387 "Not Defined" 64386 "Not Defined" 64385 "Not Defined" 64384 "Not Defined" 64383 "Not Defined" 64382 "Not Defined" 64381 "Not Defined" 64380 "Not Defined" 64379 "Not Defined" 64378 "Not Defined" 64377 "Not Defined" 64376 "Not Defined" 64375 "Not Defined" 64374 "Not Defined" 64373 "Not Defined" 64372 "Not Defined" 64371 "Not Defined" 64370 "Not Defined" 64369 "Not Defined" 64368 "Not Defined" 64367 "Not Defined" 64366 "Not Defined" 64365 "Not Defined" 64364 "Not Defined" 64363 "Not Defined" 64362 "Not Defined" 64361 "Not Defined" 64360 "Not Defined" 64359 "Not Defined" 64358 "Not Defined" 64357 "Not Defined" 64356 "Not Defined" 64355 "Not Defined" 64354 "Not Defined" 64353 "Not Defined" 64352 "Not Defined" 64351 "Not Defined" 64350 "Not Defined" 64349 "Not Defined" 64348 "Not Defined" 64347 "Not Defined" 64346 "Not Defined" 64345 "Not Defined" 64344 "Not Defined" 64343 "Not Defined" 64342 "Not Defined" 64341 "Not Defined" 64340 "Not Defined" 64339 "Not Defined" 64338 "Not Defined" 64337 "Not Defined" 64336 "Not Defined" 64335 "Not Defined" 64334 "Not Defined" 64333 "Not Defined" 64332 "Not Defined" 64331 "Not Defined" 64330 "Not Defined" 64329 "Not Defined" 64328 "Not Defined" 64327 "Not Defined" 64326 "Not Defined" 64325 "Not Defined" 64324 "Not Defined" 64323 "Not Defined" 64322 "Not Defined" 64321 "Not Defined" 64320 "Not Defined" 64319 "Not Defined" 64318 "Not Defined" 64317 "Not Defined" 64316 "Not Defined" 64315 "Not Defined" 64314 "Not Defined" 64313 "Not Defined" 64312 "Not Defined" 64311 "Not Defined" 64310 "Not Defined" 64309 "Not Defined" 64308 "Not Defined" 64307 "Not Defined" 64306 "Not Defined" 64305 "Not Defined" 64304 "Not Defined" 64303 "Not Defined" 64302 "Not Defined" 64301 "Not Defined" 64300 "Not Defined" 64299 "Not Defined" 64298 "Not Defined" 64297 "Not Defined" 64296 "Not Defined" 64295 "Not Defined" 64294 "Not Defined" 64293 "Not Defined" 64292 "Not Defined" 64291 "Not Defined" 64290 "Not Defined" 64289 "Not Defined" 64288 "Not Defined" 64287 "Not Defined" 64286 "Not Defined" 64285 "Not Defined" 64284 "Not Defined" 64283 "Not Defined" 64282 "Not Defined" 64281 "Not Defined" 64280 "Not Defined" 64279 "Not Defined" 64278 "Not Defined" 64277 "Not Defined" 64276 "Not Defined" 64275 "Not Defined" 64274 "Not Defined" 64273 "Not Defined" 64272 "Not Defined" 64271 "Not Defined" 64270 "Not Defined" 64269 "Not Defined" 64268 "Not Defined" 64267 "Not Defined" 64266 "Not Defined" 64265 "Not Defined" 64264 "Not Defined" 64263 "Not Defined" 64262 "Not Defined" 64261 "Not Defined" 64260 "Not Defined" 64259 "Not Defined" 64258 "Not Defined" 64257 "Not Defined" 64256 "Not Defined" ;
VAL_ 2680225585 PSV_SupV6_2VRef 65535 "Signal not available" 64510 "Not Defined" 64509 "Not Defined" 64508 "Not Defined" 64507 "Not Defined" 64506 "Not Defined" 64505 "Not Defined" 64504 "Not Defined" 64503 "Not Defined" 64502 "Not Defined" 64501 "Not Defined" 64500 "Not Defined" 64499 "Not Defined" 64498 "Not Defined" 64497 "Not Defined" 64496 "Not Defined" 64495 "Not Defined" 64494 "Not Defined" 64493 "Not Defined" 64492 "Not Defined" 64491 "Not Defined" 64490 "Not Defined" 64489 "Not Defined" 64488 "Not Defined" 64487 "Not Defined" 64486 "Not Defined" 64485 "Not Defined" 64484 "Not Defined" 64483 "Not Defined" 64482 "Not Defined" 64481 "Not Defined" 64480 "Not Defined" 64479 "Not Defined" 64478 "Not Defined" 64477 "Not Defined" 64476 "Not Defined" 64475 "Not Defined" 64474 "Not Defined" 64473 "Not Defined" 64472 "Not Defined" 64471 "Not Defined" 64470 "Not Defined" 64469 "Not Defined" 64468 "Not Defined" 64467 "Not Defined" 64466 "Not Defined" 64465 "Not Defined" 64464 "Not Defined" 64463 "Not Defined" 64462 "Not Defined" 64461 "Not Defined" 64460 "Not Defined" 64459 "Not Defined" 64458 "Not Defined" 64457 "Not Defined" 64456 "Not Defined" 64455 "Not Defined" 64454 "Not Defined" 64453 "Not Defined" 64452 "Not Defined" 64451 "Not Defined" 64450 "Not Defined" 64449 "Not Defined" 64448 "Not Defined" 64447 "Not Defined" 64446 "Not Defined" 64445 "Not Defined" 64444 "Not Defined" 64443 "Not Defined" 64442 "Not Defined" 64441 "Not Defined" 64440 "Not Defined" 64439 "Not Defined" 64438 "Not Defined" 64437 "Not Defined" 64436 "Not Defined" 64435 "Not Defined" 64434 "Not Defined" 64433 "Not Defined" 64432 "Not Defined" 64431 "Not Defined" 64430 "Not Defined" 64429 "Not Defined" 64428 "Not Defined" 64427 "Not Defined" 64426 "Not Defined" 64425 "Not Defined" 64424 "Not Defined" 64423 "Not Defined" 64422 "Not Defined" 64421 "Not Defined" 64420 "Not Defined" 64419 "Not Defined" 64418 "Not Defined" 64417 "Not Defined" 64416 "Not Defined" 64415 "Not Defined" 64414 "Not Defined" 64413 "Not Defined" 64412 "Not Defined" 64411 "Not Defined" 64410 "Not Defined" 64409 "Not Defined" 64408 "Not Defined" 64407 "Not Defined" 64406 "Not Defined" 64405 "Not Defined" 64404 "Not Defined" 64403 "Not Defined" 64402 "Not Defined" 64401 "Not Defined" 64400 "Not Defined" 64399 "Not Defined" 64398 "Not Defined" 64397 "Not Defined" 64396 "Not Defined" 64395 "Not Defined" 64394 "Not Defined" 64393 "Not Defined" 64392 "Not Defined" 64391 "Not Defined" 64390 "Not Defined" 64389 "Not Defined" 64388 "Not Defined" 64387 "Not Defined" 64386 "Not Defined" 64385 "Not Defined" 64384 "Not Defined" 64383 "Not Defined" 64382 "Not Defined" 64381 "Not Defined" 64380 "Not Defined" 64379 "Not Defined" 64378 "Not Defined" 64377 "Not Defined" 64376 "Not Defined" 64375 "Not Defined" 64374 "Not Defined" 64373 "Not Defined" 64372 "Not Defined" 64371 "Not Defined" 64370 "Not Defined" 64369 "Not Defined" 64368 "Not Defined" 64367 "Not Defined" 64366 "Not Defined" 64365 "Not Defined" 64364 "Not Defined" 64363 "Not Defined" 64362 "Not Defined" 64361 "Not Defined" 64360 "Not Defined" 64359 "Not Defined" 64358 "Not Defined" 64357 "Not Defined" 64356 "Not Defined" 64355 "Not Defined" 64354 "Not Defined" 64353 "Not Defined" 64352 "Not Defined" 64351 "Not Defined" 64350 "Not Defined" 64349 "Not Defined" 64348 "Not Defined" 64347 "Not Defined" 64346 "Not Defined" 64345 "Not Defined" 64344 "Not Defined" 64343 "Not Defined" 64342 "Not Defined" 64341 "Not Defined" 64340 "Not Defined" 64339 "Not Defined" 64338 "Not Defined" 64337 "Not Defined" 64336 "Not Defined" 64335 "Not Defined" 64334 "Not Defined" 64333 "Not Defined" 64332 "Not Defined" 64331 "Not Defined" 64330 "Not Defined" 64329 "Not Defined" 64328 "Not Defined" 64327 "Not Defined" 64326 "Not Defined" 64325 "Not Defined" 64324 "Not Defined" 64323 "Not Defined" 64322 "Not Defined" 64321 "Not Defined" 64320 "Not Defined" 64319 "Not Defined" 64318 "Not Defined" 64317 "Not Defined" 64316 "Not Defined" 64315 "Not Defined" 64314 "Not Defined" 64313 "Not Defined" 64312 "Not Defined" 64311 "Not Defined" 64310 "Not Defined" 64309 "Not Defined" 64308 "Not Defined" 64307 "Not Defined" 64306 "Not Defined" 64305 "Not Defined" 64304 "Not Defined" 64303 "Not Defined" 64302 "Not Defined" 64301 "Not Defined" 64300 "Not Defined" 64299 "Not Defined" 64298 "Not Defined" 64297 "Not Defined" 64296 "Not Defined" 64295 "Not Defined" 64294 "Not Defined" 64293 "Not Defined" 64292 "Not Defined" 64291 "Not Defined" 64290 "Not Defined" 64289 "Not Defined" 64288 "Not Defined" 64287 "Not Defined" 64286 "Not Defined" 64285 "Not Defined" 64284 "Not Defined" 64283 "Not Defined" 64282 "Not Defined" 64281 "Not Defined" 64280 "Not Defined" 64279 "Not Defined" 64278 "Not Defined" 64277 "Not Defined" 64276 "Not Defined" 64275 "Not Defined" 64274 "Not Defined" 64273 "Not Defined" 64272 "Not Defined" 64271 "Not Defined" 64270 "Not Defined" 64269 "Not Defined" 64268 "Not Defined" 64267 "Not Defined" 64266 "Not Defined" 64265 "Not Defined" 64264 "Not Defined" 64263 "Not Defined" 64262 "Not Defined" 64261 "Not Defined" 64260 "Not Defined" 64259 "Not Defined" 64258 "Not Defined" 64257 "Not Defined" 64256 "Not Defined" ;
VAL_ 2680225585 PSV_SupV5_Internal6V 65535 "Signal not available" 64510 "Not Defined" 64509 "Not Defined" 64508 "Not Defined" 64507 "Not Defined" 64506 "Not Defined" 64505 "Not Defined" 64504 "Not Defined" 64503 "Not Defined" 64502 "Not Defined" 64501 "Not Defined" 64500 "Not Defined" 64499 "Not Defined" 64498 "Not Defined" 64497 "Not Defined" 64496 "Not Defined" 64495 "Not Defined" 64494 "Not Defined" 64493 "Not Defined" 64492 "Not Defined" 64491 "Not Defined" 64490 "Not Defined" 64489 "Not Defined" 64488 "Not Defined" 64487 "Not Defined" 64486 "Not Defined" 64485 "Not Defined" 64484 "Not Defined" 64483 "Not Defined" 64482 "Not Defined" 64481 "Not Defined" 64480 "Not Defined" 64479 "Not Defined" 64478 "Not Defined" 64477 "Not Defined" 64476 "Not Defined" 64475 "Not Defined" 64474 "Not Defined" 64473 "Not Defined" 64472 "Not Defined" 64471 "Not Defined" 64470 "Not Defined" 64469 "Not Defined" 64468 "Not Defined" 64467 "Not Defined" 64466 "Not Defined" 64465 "Not Defined" 64464 "Not Defined" 64463 "Not Defined" 64462 "Not Defined" 64461 "Not Defined" 64460 "Not Defined" 64459 "Not Defined" 64458 "Not Defined" 64457 "Not Defined" 64456 "Not Defined" 64455 "Not Defined" 64454 "Not Defined" 64453 "Not Defined" 64452 "Not Defined" 64451 "Not Defined" 64450 "Not Defined" 64449 "Not Defined" 64448 "Not Defined" 64447 "Not Defined" 64446 "Not Defined" 64445 "Not Defined" 64444 "Not Defined" 64443 "Not Defined" 64442 "Not Defined" 64441 "Not Defined" 64440 "Not Defined" 64439 "Not Defined" 64438 "Not Defined" 64437 "Not Defined" 64436 "Not Defined" 64435 "Not Defined" 64434 "Not Defined" 64433 "Not Defined" 64432 "Not Defined" 64431 "Not Defined" 64430 "Not Defined" 64429 "Not Defined" 64428 "Not Defined" 64427 "Not Defined" 64426 "Not Defined" 64425 "Not Defined" 64424 "Not Defined" 64423 "Not Defined" 64422 "Not Defined" 64421 "Not Defined" 64420 "Not Defined" 64419 "Not Defined" 64418 "Not Defined" 64417 "Not Defined" 64416 "Not Defined" 64415 "Not Defined" 64414 "Not Defined" 64413 "Not Defined" 64412 "Not Defined" 64411 "Not Defined" 64410 "Not Defined" 64409 "Not Defined" 64408 "Not Defined" 64407 "Not Defined" 64406 "Not Defined" 64405 "Not Defined" 64404 "Not Defined" 64403 "Not Defined" 64402 "Not Defined" 64401 "Not Defined" 64400 "Not Defined" 64399 "Not Defined" 64398 "Not Defined" 64397 "Not Defined" 64396 "Not Defined" 64395 "Not Defined" 64394 "Not Defined" 64393 "Not Defined" 64392 "Not Defined" 64391 "Not Defined" 64390 "Not Defined" 64389 "Not Defined" 64388 "Not Defined" 64387 "Not Defined" 64386 "Not Defined" 64385 "Not Defined" 64384 "Not Defined" 64383 "Not Defined" 64382 "Not Defined" 64381 "Not Defined" 64380 "Not Defined" 64379 "Not Defined" 64378 "Not Defined" 64377 "Not Defined" 64376 "Not Defined" 64375 "Not Defined" 64374 "Not Defined" 64373 "Not Defined" 64372 "Not Defined" 64371 "Not Defined" 64370 "Not Defined" 64369 "Not Defined" 64368 "Not Defined" 64367 "Not Defined" 64366 "Not Defined" 64365 "Not Defined" 64364 "Not Defined" 64363 "Not Defined" 64362 "Not Defined" 64361 "Not Defined" 64360 "Not Defined" 64359 "Not Defined" 64358 "Not Defined" 64357 "Not Defined" 64356 "Not Defined" 64355 "Not Defined" 64354 "Not Defined" 64353 "Not Defined" 64352 "Not Defined" 64351 "Not Defined" 64350 "Not Defined" 64349 "Not Defined" 64348 "Not Defined" 64347 "Not Defined" 64346 "Not Defined" 64345 "Not Defined" 64344 "Not Defined" 64343 "Not Defined" 64342 "Not Defined" 64341 "Not Defined" 64340 "Not Defined" 64339 "Not Defined" 64338 "Not Defined" 64337 "Not Defined" 64336 "Not Defined" 64335 "Not Defined" 64334 "Not Defined" 64333 "Not Defined" 64332 "Not Defined" 64331 "Not Defined" 64330 "Not Defined" 64329 "Not Defined" 64328 "Not Defined" 64327 "Not Defined" 64326 "Not Defined" 64325 "Not Defined" 64324 "Not Defined" 64323 "Not Defined" 64322 "Not Defined" 64321 "Not Defined" 64320 "Not Defined" 64319 "Not Defined" 64318 "Not Defined" 64317 "Not Defined" 64316 "Not Defined" 64315 "Not Defined" 64314 "Not Defined" 64313 "Not Defined" 64312 "Not Defined" 64311 "Not Defined" 64310 "Not Defined" 64309 "Not Defined" 64308 "Not Defined" 64307 "Not Defined" 64306 "Not Defined" 64305 "Not Defined" 64304 "Not Defined" 64303 "Not Defined" 64302 "Not Defined" 64301 "Not Defined" 64300 "Not Defined" 64299 "Not Defined" 64298 "Not Defined" 64297 "Not Defined" 64296 "Not Defined" 64295 "Not Defined" 64294 "Not Defined" 64293 "Not Defined" 64292 "Not Defined" 64291 "Not Defined" 64290 "Not Defined" 64289 "Not Defined" 64288 "Not Defined" 64287 "Not Defined" 64286 "Not Defined" 64285 "Not Defined" 64284 "Not Defined" 64283 "Not Defined" 64282 "Not Defined" 64281 "Not Defined" 64280 "Not Defined" 64279 "Not Defined" 64278 "Not Defined" 64277 "Not Defined" 64276 "Not Defined" 64275 "Not Defined" 64274 "Not Defined" 64273 "Not Defined" 64272 "Not Defined" 64271 "Not Defined" 64270 "Not Defined" 64269 "Not Defined" 64268 "Not Defined" 64267 "Not Defined" 64266 "Not Defined" 64265 "Not Defined" 64264 "Not Defined" 64263 "Not Defined" 64262 "Not Defined" 64261 "Not Defined" 64260 "Not Defined" 64259 "Not Defined" 64258 "Not Defined" 64257 "Not Defined" 64256 "Not Defined" ;
